AUTOSAR XML (schema 4-3-0)
package /Schaeffler/Components/ASW_EDS_TQ250
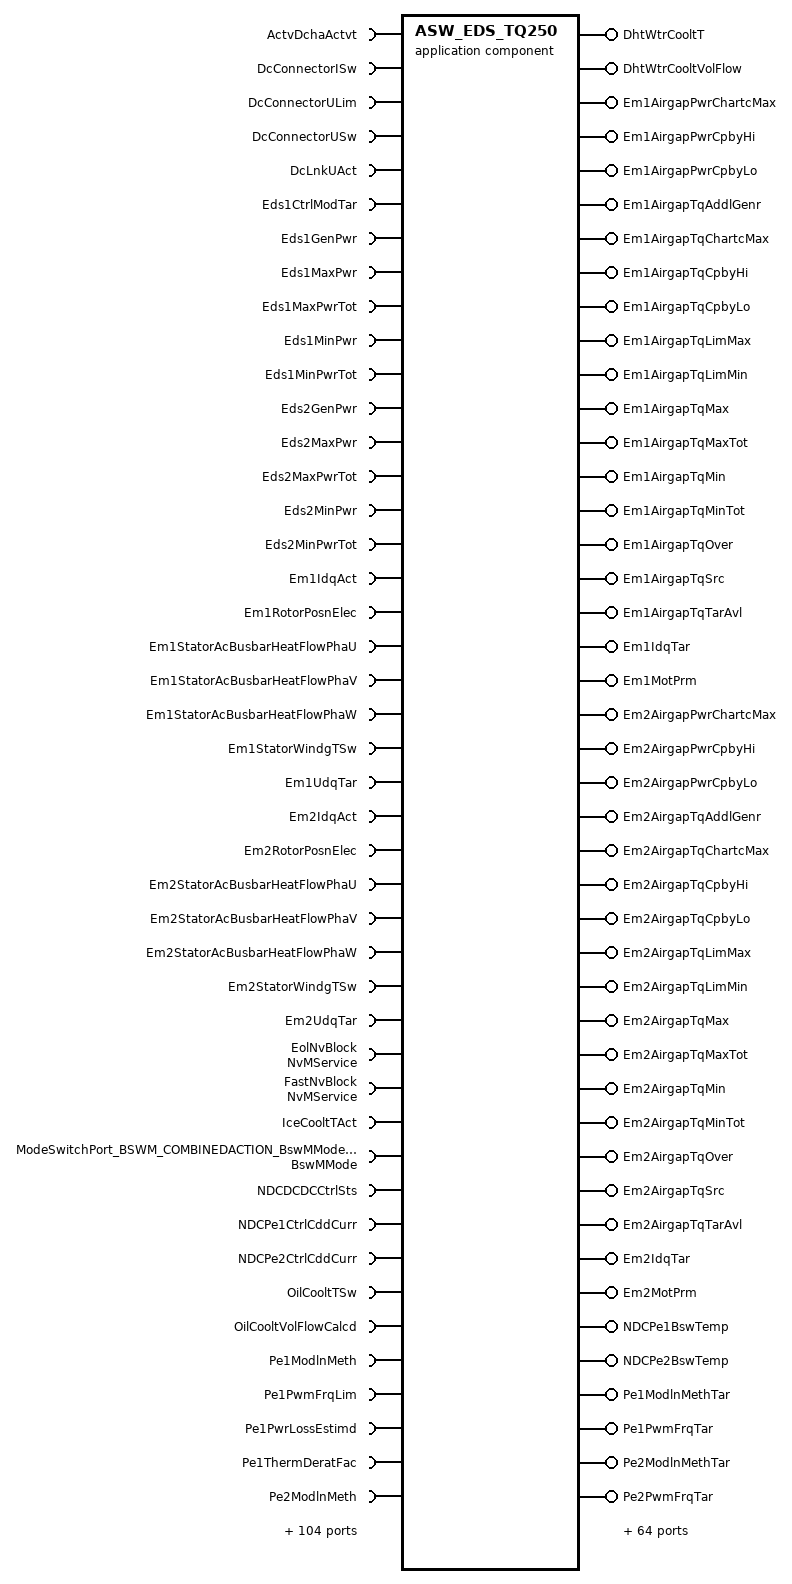
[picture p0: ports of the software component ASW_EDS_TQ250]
  application sw component type ASW_EDS_TQ250
    5 x require port:
      ActvDchaActvt: nonqueued-receiver-com-spec{data-element=FlgVal, filter=data-filter-type=ALWAYS, init-value=0}, required-interface=ActvDchaActvt
      DcConnectorISw: nonqueued-receiver-com-spec{data-element=ValSts, filter=data-filter-type=ALWAYS, init-value=fields=[0 Ampere, 0 Ampere]}, required-interface=DcConnectorISw
      DcConnectorULim: required-interface=DcConnectorULim
        required-com-specs:
          data-element=UMinValSts, filter=data-filter-type=ALWAYS, init-value=fields=[0 V, 0 V]
          data-element=UMaxValSts, filter=data-filter-type=ALWAYS, init-value=fields=[0 V, 0 V]
      DcConnectorUSw: required-interface=DcConnectorUSw
        required-com-specs:
          data-element=UVal, filter=data-filter-type=ALWAYS, init-value=0 Volt
          data-element=UQf, init-value=0
          data-element=ValSts, filter=data-filter-type=ALWAYS, init-value=fields=[0, 0]
      DcLnkUAct: nonqueued-receiver-com-spec{data-element=ValSts, filter=data-filter-type=ALWAYS, init-value=fields=[0, 0]}, required-interface=DcLnkUAct
    provide port DhtWtrCooltT: nonqueued-sender-com-spec{data-element=TTarValSts, init-value=fields=[0 degC, 0 degC]}, provided-interface=DhtWtrCooltT
    provide port DhtWtrCooltVolFlow: nonqueued-sender-com-spec{data-element=VolTarValSts, init-value=fields=[0 lpmin, 0 lpmin]}, provided-interface=DhtWtrCooltVolFlow
    11 x require port:
      Eds1CtrlModTar: nonqueued-receiver-com-spec{data-element=ModVal, filter=data-filter-type=ALWAYS, init-value=0}, required-interface=Eds1CtrlModTar
      Eds1GenPwr: nonqueued-receiver-com-spec{data-element=PwrValSts, filter=data-filter-type=ALWAYS, init-value=fields=[0 W, 0 W]}, required-interface=Eds1GenPwr
      Eds1MaxPwr: nonqueued-receiver-com-spec{data-element=PwrValSts, filter=data-filter-type=ALWAYS, init-value=fields=[0 W, 0 W]}, required-interface=Eds1MaxPwr
      Eds1MaxPwrTot: nonqueued-receiver-com-spec{data-element=PwrValSts, filter=data-filter-type=ALWAYS, init-value=fields=[0 W, 0 W]}, required-interface=Eds1MaxPwrTot
      Eds1MinPwr: nonqueued-receiver-com-spec{data-element=PwrValSts, filter=data-filter-type=ALWAYS, init-value=fields=[0 W, 0 W]}, required-interface=Eds1MinPwr
      Eds1MinPwrTot: nonqueued-receiver-com-spec{data-element=PwrValSts, filter=data-filter-type=ALWAYS, init-value=fields=[0 W, 0 W]}, required-interface=Eds1MinPwrTot
      Eds2GenPwr: nonqueued-receiver-com-spec{data-element=PwrValSts, filter=data-filter-type=ALWAYS, init-value=fields=[0 W, 0 W]}, required-interface=Eds2GenPwr
      Eds2MaxPwr: nonqueued-receiver-com-spec{data-element=PwrValSts, filter=data-filter-type=ALWAYS, init-value=fields=[0 W, 0 W]}, required-interface=Eds2MaxPwr
      Eds2MaxPwrTot: nonqueued-receiver-com-spec{data-element=PwrValSts, filter=data-filter-type=ALWAYS, init-value=fields=[0 W, 0 W]}, required-interface=Eds2MaxPwrTot
      Eds2MinPwr: nonqueued-receiver-com-spec{data-element=PwrValSts, filter=data-filter-type=ALWAYS, init-value=fields=[0 W, 0 W]}, required-interface=Eds2MinPwr
      Eds2MinPwrTot: nonqueued-receiver-com-spec{data-element=PwrValSts, filter=data-filter-type=ALWAYS, init-value=fields=[0 W, 0 W]}, required-interface=Eds2MinPwrTot
    16 x provide port:
      Em1AirgapPwrChartcMax: nonqueued-sender-com-spec{data-element=PwrMaxValSts, init-value=fields=[0 Watt, 0 Watt]}, provided-interface=Em1AirgapPwrChartcMax
      Em1AirgapPwrCpbyHi: nonqueued-sender-com-spec{data-element=PwrValSts, init-value=fields=[0 Watt, 0 Watt]}, provided-interface=Em1AirgapPwrCpbyHi
      Em1AirgapPwrCpbyLo: nonqueued-sender-com-spec{data-element=PwrValSts, init-value=fields=[0 Watt, 0 Watt]}, provided-interface=Em1AirgapPwrCpbyLo
      Em1AirgapTqAddlGenr: provided-interface=Em1AirgapTqAddlGenr
        provided-com-specs:
          data-element=TqQf, init-value=0
          data-element=TqVal, init-value=0 Nm
          data-element=TqValSts, init-value=fields=[0 Nm, 0]
      Em1AirgapTqChartcMax: nonqueued-sender-com-spec{data-element=TqMaxValSts, init-value=fields=[0 Watt, 0 Watt]}, provided-interface=Em1AirgapTqChartcMax
      Em1AirgapTqCpbyHi: nonqueued-sender-com-spec{data-element=TqValSts, init-value=fields=[0 Nm, 0 Nm]}, provided-interface=Em1AirgapTqCpbyHi
      Em1AirgapTqCpbyLo: nonqueued-sender-com-spec{data-element=TqValSts, init-value=fields=[0 Nm, 0 Nm]}, provided-interface=Em1AirgapTqCpbyLo
      Em1AirgapTqLimMax: provided-com-specs=[{data-element=TqMaxVal, init-value=0}, {data-element=TqMaxValSts, init-value=fields=[New:0, Status:0]}], provided-interface=Em1AirgapTqLimMax
      Em1AirgapTqLimMin: nonqueued-sender-com-spec{data-element=TqMinValSts, init-value=fields=[0 Nm, 0 Nm]}, provided-interface=Em1AirgapTqLimMin
      Em1AirgapTqMax: nonqueued-sender-com-spec{data-element=TqMaxValSts, init-value=fields=[0 Nm, 0 Nm]}, provided-interface=Em1AirgapTqMax
      Em1AirgapTqMaxTot: nonqueued-sender-com-spec{data-element=TqMaxValSts, init-value=fields=[0 Nm, 0 Nm]}, provided-interface=Em1AirgapTqMaxTot
      Em1AirgapTqMin: nonqueued-sender-com-spec{data-element=TqMinValSts, init-value=fields=[0 Nm, 0 Nm]}, provided-interface=Em1AirgapTqMin
      Em1AirgapTqMinTot: nonqueued-sender-com-spec{data-element=TqMinValSts, init-value=fields=[0 Nm, 0 Nm]}, provided-interface=Em1AirgapTqMinTot
      Em1AirgapTqOver: nonqueued-sender-com-spec{data-element=FlgVal, init-value=0}, provided-interface=Em1AirgapTqOver
      Em1AirgapTqSrc: nonqueued-sender-com-spec{data-element=SrcVal, init-value=0}, provided-interface=Em1AirgapTqSrc
      Em1AirgapTqTarAvl: nonqueued-sender-com-spec{data-element=TqVal, init-value=0 NwtMtr}, provided-interface=Em1AirgapTqTarAvl
    require port Em1IdqAct: required-interface=Em1IdqAct
      required-com-specs:
        data-element=IdQf, filter=data-filter-type=ALWAYS, init-value=0
        data-element=IdVal, filter=data-filter-type=ALWAYS, init-value=0 Ampere
        data-element=IqQf, filter=data-filter-type=ALWAYS, init-value=0
        data-element=IqVal, filter=data-filter-type=ALWAYS, init-value=0 Ampere
    provide port Em1IdqTar: provided-interface=Em1IdqTar
      provided-com-specs:
        data-element=IdQf, init-value=0
        data-element=IdVal, init-value=0 Ampere
        data-element=IqQf, init-value=0
        data-element=IqVal, init-value=0 Ampere
    provide port Em1MotPrm: provided-interface=Em1MotPrm
      provided-com-specs:
        data-element=FlxdQf, init-value=0
        data-element=FlxdVal, init-value=0 Weber
        data-element=FlxPrmntMagQf, init-value=0
        data-element=FlxPrmntMagVal, init-value=0.0237 Weber
        data-element=FlxqQf, init-value=0
        data-element=FlxqVal, init-value=0 Weber
        data-element=LdQf, init-value=0
        data-element=LdVal, init-value=0.00012 Henry
        data-element=LqQf, init-value=0
        data-element=LqVal, init-value=0.000277 Henry
        data-element=RVal, init-value=0.0086 Ohm
        data-element=LqDiffVal, init-value=0.000277 Henry
        data-element=LdDiffVal, init-value=0.00012 Henry
    6 x require port:
      Em1RotorPosnElec: required-interface=Em1RotorPosnElec
        required-com-specs:
          data-element=PosnQf, filter=data-filter-type=ALWAYS, init-value=0
          data-element=PosnVal, filter=data-filter-type=ALWAYS, init-value=0 rad
      Em1StatorAcBusbarHeatFlowPhaU: required-interface=Em1StatorAcBusbarHeatFlowPhaU
        required-com-specs:
          data-element=HeatFlowPhaUVal, filter=data-filter-type=ALWAYS, init-value=65 Watt
          data-element=HeatFlowPhaUValQf, filter=data-filter-type=ALWAYS, init-value=0
      Em1StatorAcBusbarHeatFlowPhaV: required-interface=Em1StatorAcBusbarHeatFlowPhaV
        required-com-specs:
          data-element=HeatFlowPhaVVal, filter=data-filter-type=ALWAYS, init-value=65 Watt
          data-element=HeatFlowPhaVValQf, filter=data-filter-type=ALWAYS, init-value=0
      Em1StatorAcBusbarHeatFlowPhaW: required-interface=Em1StatorAcBusbarHeatFlowPhaW
        required-com-specs:
          data-element=HeatFlowPhaWVal, filter=data-filter-type=ALWAYS, init-value=65 Watt
          data-element=HeatFlowPhaWValQf, filter=data-filter-type=ALWAYS, init-value=0
      Em1StatorWindgTSw: nonqueued-receiver-com-spec{data-element=TValSts, init-value=fields=[0 degC, 0 degC]}, required-interface=Em1StatorWindgTSw
      Em1UdqTar: required-interface=Em1UdqTar
        required-com-specs:
          data-element=UdVal, filter=data-filter-type=ALWAYS, init-value=0 Volt
          data-element=UqVal, filter=data-filter-type=ALWAYS, init-value=0 Volt
    16 x provide port:
      Em2AirgapPwrChartcMax: nonqueued-sender-com-spec{data-element=PwrMaxValSts, init-value=fields=[0 Watt, 0 Watt]}, provided-interface=Em2AirgapPwrChartcMax
      Em2AirgapPwrCpbyHi: nonqueued-sender-com-spec{data-element=PwrValSts, init-value=fields=[0 Watt, 0 Watt]}, provided-interface=Em2AirgapPwrCpbyHi
      Em2AirgapPwrCpbyLo: nonqueued-sender-com-spec{data-element=PwrValSts, init-value=fields=[0 Watt, 0 Watt]}, provided-interface=Em2AirgapPwrCpbyLo
      Em2AirgapTqAddlGenr: nonqueued-sender-com-spec{data-element=TqValSts, init-value=fields=[0 Nm, 0]}, provided-interface=Em2AirgapTqAddlGenr
      Em2AirgapTqChartcMax: nonqueued-sender-com-spec{data-element=TqMaxValSts, init-value=fields=[0 Nm, 0 Nm]}, provided-interface=Em2AirgapTqChartcMax
      Em2AirgapTqCpbyHi: nonqueued-sender-com-spec{data-element=TqValSts, init-value=fields=[0 Nm, 0 Nm]}, provided-interface=Em2AirgapTqCpbyHi
      Em2AirgapTqCpbyLo: nonqueued-sender-com-spec{data-element=TqValSts, init-value=fields=[0 Nm, 0 Nm]}, provided-interface=Em2AirgapTqCpbyLo
      Em2AirgapTqLimMax: nonqueued-sender-com-spec{data-element=TqMaxValSts, init-value=fields=[0 Nm, 0 Nm]}, provided-interface=Em2AirgapTqLimMax
      Em2AirgapTqLimMin: nonqueued-sender-com-spec{data-element=TqMinValSts, init-value=fields=[0 Nm, 0 Nm]}, provided-interface=Em2AirgapTqLimMin
      Em2AirgapTqMax: nonqueued-sender-com-spec{data-element=TqMaxValSts, init-value=fields=[1023 Nm, 0 Nm]}, provided-interface=Em2AirgapTqMax
      Em2AirgapTqMaxTot: nonqueued-sender-com-spec{data-element=TqMaxValSts, init-value=fields=[0 Nm, 0 Nm]}, provided-interface=Em2AirgapTqMaxTot
      Em2AirgapTqMin: nonqueued-sender-com-spec{data-element=TqMinValSts, init-value=fields=[1023 Nm, 0 Nm]}, provided-interface=Em2AirgapTqMin
      Em2AirgapTqMinTot: nonqueued-sender-com-spec{data-element=TqMinValSts, init-value=fields=[0 Nm, 0 Nm]}, provided-interface=Em2AirgapTqMinTot
      Em2AirgapTqOver: nonqueued-sender-com-spec{data-element=FlgVal, init-value=0}, provided-interface=Em2AirgapTqOver
      Em2AirgapTqSrc: nonqueued-sender-com-spec{data-element=SrcVal, init-value=0}, provided-interface=Em2AirgapTqSrc
      Em2AirgapTqTarAvl: nonqueued-sender-com-spec{data-element=TqVal, init-value=0 NwtMtr}, provided-interface=Em2AirgapTqTarAvl
    require port Em2IdqAct: required-interface=Em2IdqAct
      required-com-specs:
        data-element=IdQf, filter=data-filter-type=ALWAYS, init-value=0
        data-element=IdVal, filter=data-filter-type=ALWAYS, init-value=0 Ampere
        data-element=IqQf, filter=data-filter-type=ALWAYS, init-value=0
        data-element=IqVal, filter=data-filter-type=ALWAYS, init-value=0 Ampere
    provide port Em2IdqTar: provided-interface=Em2IdqTar
      provided-com-specs:
        data-element=IdQf, init-value=0
        data-element=IdVal, init-value=0 Ampere
        data-element=IqQf, init-value=0
        data-element=IqVal, init-value=0 Ampere
    provide port Em2MotPrm: provided-interface=Em2MotPrm
      provided-com-specs:
        data-element=FlxdQf, init-value=0
        data-element=FlxdVal, init-value=0 Weber
        data-element=FlxPrmntMagQf, init-value=0
        data-element=FlxPrmntMagVal, init-value=0.064 Weber
        data-element=FlxqQf, init-value=0
        data-element=FlxqVal, init-value=0 Weber
        data-element=LdQf, init-value=0
        data-element=LdVal, init-value=0.000166 Henry
        data-element=LqQf, init-value=0
        data-element=LqVal, init-value=0.000503 Henry
        data-element=RVal, init-value=0.011 Ohm
        data-element=LqDiffVal, init-value=0.000503 Henry
        data-element=LdDiffVal, init-value=0.000166 Henry
    11 x require port:
      Em2RotorPosnElec: required-interface=Em2RotorPosnElec
        required-com-specs:
          data-element=PosnQf, filter=data-filter-type=ALWAYS, init-value=0
          data-element=PosnVal, filter=data-filter-type=ALWAYS, init-value=0 rad
      Em2StatorAcBusbarHeatFlowPhaU: required-interface=Em2StatorAcBusbarHeatFlowPhaU
        required-com-specs:
          data-element=HeatFlowPhaUVal, filter=data-filter-type=ALWAYS, init-value=65 Watt
          data-element=HeatFlowPhaUValQf, filter=data-filter-type=ALWAYS, init-value=0
      Em2StatorAcBusbarHeatFlowPhaV: required-interface=Em2StatorAcBusbarHeatFlowPhaV
        required-com-specs:
          data-element=HeatFlowPhaVVal, filter=data-filter-type=ALWAYS, init-value=65 Watt
          data-element=HeatFlowPhaVValQf, filter=data-filter-type=ALWAYS, init-value=0
      Em2StatorAcBusbarHeatFlowPhaW: required-interface=Em2StatorAcBusbarHeatFlowPhaW
        required-com-specs:
          data-element=HeatFlowPhaWVal, filter=data-filter-type=ALWAYS, init-value=65 Watt
          data-element=HeatFlowPhaWValQf, filter=data-filter-type=ALWAYS, init-value=0
      Em2StatorWindgTSw: nonqueued-receiver-com-spec{data-element=TValSts, filter=data-filter-type=ALWAYS, init-value=fields=[0 degC, 0 degC]}, required-interface=Em2StatorWindgTSw
      Em2UdqTar: required-interface=Em2UdqTar
        required-com-specs:
          data-element=UdVal, filter=data-filter-type=ALWAYS, init-value=0 Volt
          data-element=UqVal, filter=data-filter-type=ALWAYS, init-value=0 Volt
      EolNvBlock: client-com-spec=SetRamBlockStatus, required-interface=NvMService
      FastNvBlock: client-com-spec=SetRamBlockStatus, required-interface=NvMService
      IceCooltTAct: required-interface=IceCooltTAct
        required-com-specs:
          data-element=TVal, filter=data-filter-type=ALWAYS, init-value=0 degC
          data-element=ValSts, init-value=fields=[0 degC, 0]
      ModeSwitchPort_BSWM_COMBINEDACTION_BswMMode_PortInterfaces_BswMMode: mode-switch-receiver-com-spec=CurrentMode, required-interface=BswMMode
      NDCDCDCCtrlSts: nonqueued-receiver-com-spec{data-element=DCDCStatus, filter=data-filter-type=ALWAYS, init-value=0}, required-interface=NDCDCDCCtrlSts
    provide port NDCPe1BswTemp: provided-interface=NDCPe1BswTemp
      provided-com-specs:
        data-element=AcBusbarTEstimdPhaUVal, init-value=20 DegCgrd
        data-element=AcBusbarTEstimdPhaVVal, init-value=20 DegCgrd
        data-element=AcBusbarTEstimdPhaWVal, init-value=20 DegCgrd
    require port NDCPe1CtrlCddCurr: required-interface=NDCPe1CtrlCddCurr
      required-com-specs:
        data-element=IdcVal, filter=data-filter-type=ALWAYS, init-value=0 Ampere
        data-element=IdcValSts, filter=data-filter-type=ALWAYS, init-value=fields=[0 A, 0 A]
    provide port NDCPe2BswTemp: provided-interface=NDCPe2BswTemp
      provided-com-specs:
        data-element=AcBusbarTEstimdPhaUVal, init-value=20 DegCgrd
        data-element=AcBusbarTEstimdPhaVVal, init-value=20 DegCgrd
        data-element=AcBusbarTEstimdPhaWVal, init-value=20 DegCgrd
    4 x require port:
      NDCPe2CtrlCddCurr: required-interface=NDCPe2CtrlCddCurr
        required-com-specs:
          data-element=IdcVal, filter=data-filter-type=ALWAYS, init-value=0 Ampere
          data-element=IdcValSts, filter=data-filter-type=ALWAYS, init-value=fields=[0 A, 0 A]
      OilCooltTSw: nonqueued-receiver-com-spec{data-element=TValSts, filter=data-filter-type=ALWAYS, init-value=fields=[0 degC, 0 degC]}, required-interface=OilCooltTSw
      OilCooltVolFlowCalcd: nonqueued-receiver-com-spec{data-element=VolFlowValSts, filter=data-filter-type=ALWAYS, init-value=fields=[0 lpmin, 0 lpmin]}, required-interface=OilCooltVolFlowCalcd
      Pe1ModlnMeth: nonqueued-receiver-com-spec{data-element=ModlnMeth, filter=data-filter-type=ALWAYS, init-value=1}, required-interface=Pe1ModlnMeth
    provide port Pe1ModlnMethTar: nonqueued-sender-com-spec{data-element=Val, init-value=1}, provided-interface=Pe1ModlnMethTar
    require port Pe1PwmFrqLim: required-interface=Pe1PwmFrqLim
      required-com-specs:
        data-element=FrqMaxVal, filter=data-filter-type=ALWAYS, init-value=10000 Hz
        data-element=FrqMinVal, filter=data-filter-type=ALWAYS, init-value=10000 Hz
    provide port Pe1PwmFrqTar: nonqueued-sender-com-spec{data-element=FrqVal, init-value=10000 Hz}, provided-interface=Pe1PwmFrqTar
    require port Pe1PwrLossEstimd: required-interface=Pe1PwrLossEstimd
      required-com-specs:
        data-element=PwrVal, filter=data-filter-type=ALWAYS, init-value=0 Watt
        data-element=PwrValQf, filter=data-filter-type=ALWAYS, init-value=0
    require port Pe1ThermDeratFac: required-interface=Pe1ThermDeratFac
      required-com-specs:
        data-element=MaxVal, filter=data-filter-type=ALWAYS, init-value=1 Perc
        data-element=MaxValSts, filter=data-filter-type=ALWAYS, init-value=fields=[0, 0]
    require port Pe2ModlnMeth: nonqueued-receiver-com-spec{data-element=ModlnMeth, filter=data-filter-type=ALWAYS, init-value=1}, required-interface=Pe2ModlnMeth
    provide port Pe2ModlnMethTar: nonqueued-sender-com-spec{data-element=Val, init-value=1 State}, provided-interface=Pe2ModlnMethTar
    require port Pe2PwmFrqLim: required-interface=Pe2PwmFrqLim
      required-com-specs:
        data-element=FrqMaxVal, filter=data-filter-type=ALWAYS, init-value=10000 Hz
        data-element=FrqMinVal, filter=data-filter-type=ALWAYS, init-value=10000 Hz
    provide port Pe2PwmFrqTar: nonqueued-sender-com-spec{data-element=FrqVal, init-value=10000 Hz}, provided-interface=Pe2PwmFrqTar
    8 x require port:
      Pe2PwrLossEstimd: required-interface=Pe2PwrLossEstimd
        required-com-specs:
          data-element=PwrVal, filter=data-filter-type=ALWAYS, init-value=0 Watt
          data-element=PwrValQf, filter=data-filter-type=ALWAYS, init-value=0
      Pe2ThermDeratFac: required-interface=Pe2ThermDeratFac
        required-com-specs:
          data-element=MaxVal, filter=data-filter-type=ALWAYS, init-value=1 Perc
          data-element=MaxValSts, init-value=fields=[0, 0]
      PeDcDcCnvrTDeratFac: required-interface=PeDcDcCnvrTDeratFac
        required-com-specs:
          data-element=FacVal, filter=data-filter-type=ALWAYS, init-value=1
          data-element=FacValSts, init-value=fields=[0, 0]
      PeWtrCooltOutlTEstimd: required-interface=PeWtrCooltOutlTEstimd
        required-com-specs:
          data-element=TVal, filter=data-filter-type=ALWAYS, init-value=20 degC
          data-element=TValQf, filter=data-filter-type=ALWAYS, init-value=0
      PeWtrCooltTTar: nonqueued-receiver-com-spec{data-element=TVal, filter=data-filter-type=ALWAYS, init-value=20 DegCgrd}, required-interface=PeWtrCooltTTar
      PeWtrCooltVolFlowTar: nonqueued-receiver-com-spec{data-element=VolFlowVal, filter=data-filter-type=ALWAYS, init-value=8 lppermin}, required-interface=PeWtrCooltVolFlowTar
      RlySts: nonqueued-receiver-com-spec{data-element=StsVal, filter=data-filter-type=ALWAYS, init-value=0}, required-interface=RlySts
      SafeNvBlock: client-com-spec=SetRamBlockStatus, required-interface=NvMService
    provide port SmpOilTEstimd: nonqueued-sender-com-spec{data-element=TValSts, init-value=fields=[0 degC, 0 degC]}, provided-interface=SmpOilTEstimd
    provide port TOilCooltVolFlow: nonqueued-sender-com-spec{data-element=VolTarValSts, init-value=fields=[0 lpmin, 0 lpmin]}, provided-interface=TOilCooltVolFlow
    require port ToothNr: nonqueued-receiver-com-spec{data-element=NrVal, filter=data-filter-type=ALWAYS, init-value=0}, required-interface=ToothNr
    require port UR_ComMUser_0: client-com-spec=RequestComMode, required-interface=ComM_UserRequest
    require port VehTiOff: nonqueued-receiver-com-spec{data-element=TiValSts, filter=data-filter-type=ALWAYS, init-value=fields=[0 min, 0 min]}, required-interface=VehTiOff
    provide port Em2TqCtrlModActvt: nonqueued-sender-com-spec{data-element=PECInIf_b_tqCtl_VW, init-value=0}, provided-interface=PECInIf_b_tqCtl_VW
    require port Em2AirgapTqDampgSts: nonqueued-receiver-com-spec{data-element=PECOutIf_bDampCtl_VW, init-value=0}, required-interface=PECOutIf_bDampCtl_VW
    require port Em2AirgapTqTarTot: nonqueued-receiver-com-spec{data-element=PECOutIf_tqSp_VW, init-value=0 NwtMtr}, required-interface=PECOutIf_tqSp_VW
    require port Em2AirgapTqLimLo: nonqueued-receiver-com-spec{data-element=PECOutIf_tqSpSpdlMin_VW, init-value=0 NwtMtr}, required-interface=PECOutIf_tqSpSpdlMin_VW
    provide port AswReadyForShutdown: nonqueued-sender-com-spec{data-element=FlgVal, init-value=0}, provided-interface=AswReadyForShutdown
    11 x require port:
      DcConnectorILim: required-interface=DcConnectorILim
        required-com-specs:
          data-element=MinIValSts, filter=data-filter-type=ALWAYS, init-value=fields=[0 V, 0 A]
          data-element=MaxIValSts, filter=data-filter-type=ALWAYS, init-value=fields=[0 A, 0 A]
      Pe1PhaIAcRmsSwPhaU: nonqueued-receiver-com-spec{data-element=IVal, filter=data-filter-type=ALWAYS, init-value=0 Ampere}, required-interface=Pe1PhaIAcRmsSwPhaU
      Pe1PhaIAcRmsSwPhaV: nonqueued-receiver-com-spec{data-element=IVal, filter=data-filter-type=ALWAYS, init-value=0 Ampere}, required-interface=Pe1PhaIAcRmsSwPhaV
      Pe1PhaIAcRmsSwPhaW: nonqueued-receiver-com-spec{data-element=IVal, filter=data-filter-type=ALWAYS, init-value=0 Ampere}, required-interface=Pe1PhaIAcRmsSwPhaW
      Pe2PhaIAcRmsSwPhaU: nonqueued-receiver-com-spec{data-element=IVal, filter=data-filter-type=ALWAYS, init-value=0 Ampere}, required-interface=Pe2PhaIAcRmsSwPhaU
      Pe2PhaIAcRmsSwPhaV: nonqueued-receiver-com-spec{data-element=IVal, filter=data-filter-type=ALWAYS, init-value=0 Ampere}, required-interface=Pe2PhaIAcRmsSwPhaV
      Pe2PhaIAcRmsSwPhaW: nonqueued-receiver-com-spec{data-element=IVal, filter=data-filter-type=ALWAYS, init-value=0 Ampere}, required-interface=Pe2PhaIAcRmsSwPhaW
      AmbTAct: required-interface=AmbTAct
        required-com-specs:
          data-element=TVal, init-value=20 DegCgrd
          data-element=ValSts, filter=data-filter-type=ALWAYS, init-value=fields=[0 degC, 0]
      Em1AirgapTqTar: nonqueued-receiver-com-spec{data-element=TqValSts, filter=data-filter-type=ALWAYS, init-value=fields=[0 Nm, 0 Nm]}, required-interface=Em1AirgapTqTar
      Em2AirgapTqTar: required-interface=Em2AirgapTqTar
        required-com-specs:
          data-element=TqVal, filter=data-filter-type=ALWAYS, init-value=0 NwtMtr
          data-element=TqValSts, filter=data-filter-type=ALWAYS, init-value=fields=[0 Nm, 0 Nm]
      WtrCooltInlVolFlowAct: required-interface=WtrCooltInlVolFlowAct
        required-com-specs:
          data-element=VolVal, filter=data-filter-type=ALWAYS, init-value=0 lppermin
          data-element=ValSts, filter=data-filter-type=ALWAYS, init-value=fields=[0 lpmin, 0 lpmin]
    5 x provide port:
      EM1DetnFreeVolt: nonqueued-sender-com-spec{data-element=StsVal, init-value=0 State}, provided-interface=EM1DetnFreeVolt
      EM1DetnOpenHVWire: nonqueued-sender-com-spec{data-element=StsVal, init-value=0 State}, provided-interface=EM1DetnOpenHVWire
      EM2DetnFreeVolt: nonqueued-sender-com-spec{data-element=StsVal, init-value=0 State}, provided-interface=EM2DetnFreeVolt
      EM2DetnOpenHVWire: nonqueued-sender-com-spec{data-element=StsVal, init-value=0 State}, provided-interface=EM2DetnOpenHVWire
      DcLnkUTar: provided-com-specs=[{data-element=UVal, init-value=0 Volt}, {data-element=ValSts, init-value=fields=[0 V, 0 V]}], provided-interface=DcLnkUTar
    12 x require port:
      Eds2CtrlModTar: nonqueued-receiver-com-spec{data-element=ModVal, filter=data-filter-type=ALWAYS, init-value=0}, required-interface=Eds2CtrlModTar
      Em1CurrMaxLim: required-interface=Em1CurrMaxLim
        required-com-specs:
          data-element=IMaxVal, filter=data-filter-type=ALWAYS, init-value=0
          data-element=IMaxValSts, filter=data-filter-type=ALWAYS, init-value=fields=[0 A, 0 A]
      Em1CurrMinLim: required-interface=Em1CurrMinLim
        required-com-specs:
          data-element=IMinVal, filter=data-filter-type=ALWAYS, init-value=0
          data-element=IMinValSts, filter=data-filter-type=ALWAYS, init-value=fields=[0 A, 0 A]
      Em1VoltMaxLim: required-interface=Em1VoltMaxLim
        required-com-specs:
          data-element=UMaxVal, filter=data-filter-type=ALWAYS, init-value=0
          data-element=UMaxValSts, filter=data-filter-type=ALWAYS, init-value=fields=[0 V, 0 V]
      Em1VoltMinLim: required-interface=Em1VoltMinLim
        required-com-specs:
          data-element=UMinVal, filter=data-filter-type=ALWAYS, init-value=0
          data-element=UMinValSts, filter=data-filter-type=ALWAYS, init-value=fields=[0 V, 0 V]
      Em2CurrMaxLim: required-interface=Em2CurrMaxLim
        required-com-specs:
          data-element=IMaxVal, filter=data-filter-type=ALWAYS, init-value=0
          data-element=IMaxValSts, filter=data-filter-type=ALWAYS, init-value=fields=[0 A, 0 A]
      Em2CurrMinLim: required-interface=Em2CurrMinLim
        required-com-specs:
          data-element=IMinVal, filter=data-filter-type=ALWAYS, init-value=0
          data-element=IMinValSts, filter=data-filter-type=ALWAYS, init-value=fields=[0 A, 0 A]
      Em2VoltMaxLim: required-interface=Em2VoltMaxLim
        required-com-specs:
          data-element=UMaxVal, filter=data-filter-type=ALWAYS, init-value=0
          data-element=UMaxValSts, filter=data-filter-type=ALWAYS, init-value=fields=[0 V, 0 V]
      Em2VoltMinLim: required-interface=Em2VoltMinLim
        required-com-specs:
          data-element=UMinVal, filter=data-filter-type=ALWAYS, init-value=0
          data-element=UMinValSts, filter=data-filter-type=ALWAYS, init-value=fields=[0 V, 0 V]
      Em2TqLimTracCtrl: required-interface=Em2TqLimTracCtrl
        required-com-specs:
          data-element=TqMinVal, filter=data-filter-type=ALWAYS, init-value=0 Nm
          data-element=TqMaxVal, filter=data-filter-type=ALWAYS, init-value=0 Nm
      Em2SpdAct: required-interface=Em2SpdAct
        required-com-specs:
          data-element=SpdQf, filter=data-filter-type=ALWAYS, init-value=0
          data-element=SpdVal, filter=data-filter-type=ALWAYS, init-value=0 Rpm
      Em1SpdAct: required-interface=Em1SpdAct
        required-com-specs:
          data-element=SpdQf, filter=data-filter-type=ALWAYS, init-value=0
          data-element=SpdVal, filter=data-filter-type=ALWAYS, init-value=0 Rpm
    6 x provide port:
      Em1SpdActvScLoInit: nonqueued-sender-com-spec{data-element=SpdValSts, init-value=fields=[0 Rpm, 0 Rpm]}, provided-interface=Em1SpdActvScLoInit
      Em2SpdActvScLoInit: nonqueued-sender-com-spec{data-element=SpdValSts, init-value=fields=[0 Rpm, 0 Rpm]}, provided-interface=Em2SpdActvScLoInit
      DcDcModeTar: nonqueued-sender-com-spec{data-element=StsVal, init-value=0}, provided-interface=DcDcModeTar
      Em1ActvDchaSrcQm: nonqueued-sender-com-spec{data-element=FlgVal, init-value=0}, provided-interface=Em1ActvDchaSrcQm
      Em1PwmDcSrcQm: nonqueued-sender-com-spec{data-element=SrcVal, init-value=1}, provided-interface=Em1PwmDcSrcQm
      Em2PwmDcSrcQm: nonqueued-sender-com-spec{data-element=SrcVal, init-value=1}, provided-interface=Em2PwmDcSrcQm
    14 x require port:
      R_MonAProtSpdOutLimHiEm1: required-interface=DiagnosticInfo
        required-com-specs:
          GetEventExtendedDataRecord
          GetEventFreezeFrameData
          GetFaultDetectionCounter
          GetDTCOfEvent
          GetEventTested
          GetEventFailed
          GetEventStatus
          GetEventUdsStatus
          GetMonitorStatus
          GetEventAvailable
          GetEventFreezeFrameDataEx
          GetEventExtendedDataRecordEx
          GetDebouncingOfEvent
      R_MonAProtSpdOutLimHiEm2: required-interface=DiagnosticInfo
        required-com-specs:
          GetEventExtendedDataRecord
          GetEventFreezeFrameData
          GetFaultDetectionCounter
          GetDTCOfEvent
          GetEventTested
          GetEventFailed
          GetEventStatus
          GetEventUdsStatus
          GetMonitorStatus
          GetEventAvailable
          GetEventFreezeFrameDataEx
          GetEventExtendedDataRecordEx
          GetDebouncingOfEvent
      R_MonAProtTempOutLimHiEm1: required-interface=DiagnosticInfo
        required-com-specs:
          GetEventExtendedDataRecord
          GetEventFreezeFrameData
          GetFaultDetectionCounter
          GetDTCOfEvent
          GetEventTested
          GetEventFailed
          GetEventStatus
          GetEventUdsStatus
          GetMonitorStatus
          GetEventAvailable
          GetEventFreezeFrameDataEx
          GetEventExtendedDataRecordEx
          GetDebouncingOfEvent
      P_MonAProtTempOutLimHiEm1: required-interface=DiagnosticMonitor
        required-com-specs:
          ClearPrestoredFreezeFrame
          PrestoreFreezeFrame
          ResetEventDebounceStatus
          ResetEventStatus
          SetEventStatus
          SetEventDisabled
      P_MonAProtSpdOutLimHiEm1: required-interface=DiagnosticMonitor
        required-com-specs:
          ClearPrestoredFreezeFrame
          PrestoreFreezeFrame
          ResetEventDebounceStatus
          ResetEventStatus
          SetEventStatus
          SetEventDisabled
      P_MonAProtSpdOutLimHiEm2: required-interface=DiagnosticMonitor
        required-com-specs:
          ClearPrestoredFreezeFrame
          PrestoreFreezeFrame
          ResetEventDebounceStatus
          ResetEventStatus
          SetEventStatus
          SetEventDisabled
      R_MonAProtTempOutLimHiEm2: required-interface=DiagnosticInfo
        required-com-specs:
          GetEventExtendedDataRecord
          GetEventFreezeFrameData
          GetFaultDetectionCounter
          GetDTCOfEvent
          GetEventTested
          GetEventFailed
          GetEventStatus
          GetEventUdsStatus
          GetMonitorStatus
          GetEventAvailable
          GetEventFreezeFrameDataEx
          GetEventExtendedDataRecordEx
          GetDebouncingOfEvent
      P_MonAProtTempOutLimHiEm2: required-interface=DiagnosticMonitor
        required-com-specs:
          ClearPrestoredFreezeFrame
          PrestoreFreezeFrame
          ResetEventDebounceStatus
          ResetEventStatus
          SetEventStatus
          SetEventDisabled
      Em2AirgapTqAllwdMin: nonqueued-receiver-com-spec{data-element=TqMinValSts, filter=data-filter-type=ALWAYS, init-value=fields=[0 Nm, 0 Nm]}, required-interface=Em2AirgapTqAllwdMin
      Em2AirgapTqAllwdMax: nonqueued-receiver-com-spec{data-element=TqMaxValSts, filter=data-filter-type=ALWAYS, init-value=fields=[0 Nm, 0 Nm]}, required-interface=Em2AirgapTqAllwdMax
      Em1AirgapTqAllwdMax: nonqueued-receiver-com-spec{data-element=TqMaxValSts, filter=data-filter-type=ALWAYS, init-value=fields=[0 Nm, 0 Nm]}, required-interface=Em1AirgapTqAllwdMax
      Em1AirgapTqAllwdMin: nonqueued-receiver-com-spec{data-element=TqMinValSts, filter=data-filter-type=ALWAYS, init-value=fields=[0 Nm, 0 Nm]}, required-interface=Em1AirgapTqAllwdMin
      DcDcCnvrPwrLossEstimdMax: required-interface=DcDcCnvrPwrLossEstimdMax
        required-com-specs:
          data-element=PwrValQf, filter=data-filter-type=ALWAYS, init-value=0
          data-element=PwrVal, filter=data-filter-type=ALWAYS, init-value=0 Watt
      DcDcCnvrPwrLossEstimdMin: required-interface=DcDcCnvrPwrLossEstimdMin
        required-com-specs:
          data-element=PwrValQf, filter=data-filter-type=ALWAYS, init-value=0
          data-element=PwrVal, filter=data-filter-type=ALWAYS, init-value=0 Watt
    provide port DclnkILim: provided-interface=DclnkILim
      provided-com-specs:
        data-element=IMinValSts, init-value=fields=[0 Ampere, 0 Ampere]
        data-element=IMaxValSts, init-value=fields=[0 Ampere, 0 Ampere]
    require port DcLnkUTarUCtrl: required-interface=DcLnkUTarUCtrl
      required-com-specs:
        data-element=UVal, filter=data-filter-type=ALWAYS, init-value=0 Volt
        data-element=UQf, filter=data-filter-type=ALWAYS, init-value=0
    require port ReqActvDchaSy: nonqueued-receiver-com-spec{data-element=FlgVal, filter=data-filter-type=ALWAYS, init-value=0 State}, required-interface=ReqActvDchaSy
    provide port Eds1CtrlModActQm: nonqueued-sender-com-spec{data-element=ModVal, init-value=0}, provided-interface=Eds1CtrlModActQm
    provide port Eds2CtrlModActQm: nonqueued-sender-com-spec{data-element=ModVal, init-value=0}, provided-interface=Eds2CtrlModActQm
    require port VehVAct: required-interface=VehVAct
      required-com-specs:
        data-element=QBit, filter=data-filter-type=ALWAYS, init-value=0
        data-element=VVal, filter=data-filter-type=ALWAYS, init-value=0 kmph
        data-element=ValSts, init-value=fields=[0 kmph, 0]
    provide port InsMonError: nonqueued-sender-com-spec{data-element=StsVal, init-value=1 State}, provided-interface=InsMonError
    require port ActiveReactions: nonqueued-receiver-com-spec{data-element=Status, filter=data-filter-type=ALWAYS, init-value=0}, required-interface=ActiveReactions
    5 x provide port:
      Asw1msEvents: nonqueued-sender-com-spec{data-element=Status, init-value=20 x 255}, provided-interface=Asw1msEvents
      Asw250msEvents: nonqueued-sender-com-spec{data-element=Status, init-value=23 x 255}, provided-interface=Asw250msEvents
      Em2SpdAbs: nonqueued-sender-com-spec{data-element=PECInIf_nAbs_VW, init-value=0}, provided-interface=PECInIf_nAbs_VW
      PECInIf_tqMax_VW: nonqueued-sender-com-spec{data-element=PECInIf_tqMax_VW, init-value=0}, provided-interface=PECInIf_tqMax_VW
      PECInIf_tqMin_VW: nonqueued-sender-com-spec{data-element=PECInIf_tqMin_VW, init-value=0}, provided-interface=PECInIf_tqMin_VW
    require port Em1PwrStModeAct: nonqueued-receiver-com-spec{data-element=ModVal, filter=data-filter-type=ALWAYS, init-value=0}, required-interface=Em1PwrStModeAct
    require port Em2PwrStModeAct: nonqueued-receiver-com-spec{data-element=ModVal, filter=data-filter-type=ALWAYS, init-value=0}, required-interface=Em2PwrStModeAct
    provide port Em1BattShutDwn: nonqueued-sender-com-spec{data-element=StsVal, init-value=0}, provided-interface=Em1BattShutDwn
    require port Eds1AirgapTqReq: nonqueued-receiver-com-spec{data-element=FlgVal, filter=data-filter-type=ALWAYS, init-value=0}, required-interface=Eds1AirgapTqReq
    13 x provide port:
      Em2BattShutDwn: nonqueued-sender-com-spec{data-element=StsVal, init-value=0}, provided-interface=Em2BattShutDwn
      Em1AscErrorReaction: nonqueued-sender-com-spec{data-element=StsVal, init-value=0}, provided-interface=Em1AscErrorReaction
      Em2AscErrorReaction: nonqueued-sender-com-spec{data-element=StsVal, init-value=0}, provided-interface=Em2AscErrorReaction
      Em1FwErrorReaction: nonqueued-sender-com-spec{data-element=StsVal, init-value=0}, provided-interface=Em1FwErrorReaction
      Em2FwErrorReaction: nonqueued-sender-com-spec{data-element=StsVal, init-value=0}, provided-interface=Em2FwErrorReaction
      Em1AirgapTqEstimdQm: provided-com-specs=[{data-element=TqVal, init-value=0 Nm}, {data-element=TqQf, init-value=0}], provided-interface=Em1AirgapTqEstimdQm
      Em2AirgapTqEstimdQm: provided-com-specs=[{data-element=TqVal, init-value=0 Nm}, {data-element=TqQf, init-value=0}], provided-interface=Em2AirgapTqEstimdQm
      Eds1PwrPerformanceIndcr: nonqueued-sender-com-spec{data-element=PwrIndcrValSts, init-value=fields=[0 Percent, 0 Percent]}, provided-interface=Eds1PwrPerformanceIndcr
      Eds1TempPerformanceIndcr: nonqueued-sender-com-spec{data-element=TempIndcrValSts, init-value=fields=[0 Percent, 0 Percent]}, provided-interface=Eds1TempPerformanceIndcr
      Eds1TqPerformanceIndcr: nonqueued-sender-com-spec{data-element=TqIndcrValSts, init-value=fields=[0 Percent, 0 Percent]}, provided-interface=Eds1TqPerformanceIndcr
      Eds2PwrPerformanceIndcr: nonqueued-sender-com-spec{data-element=PwrIndcrValSts, init-value=fields=[0 Percent, 0 Percent]}, provided-interface=Eds2PwrPerformanceIndcr
      Eds2TempPerformanceIndcr: nonqueued-sender-com-spec{data-element=TempIndcrValSts, init-value=fields=[0 Percent, 0 Percent]}, provided-interface=Eds2TempPerformanceIndcr
      Eds2TqPerformanceIndcr: nonqueued-sender-com-spec{data-element=TqIndcrValSts, init-value=fields=[0 Percent, 0 Percent]}, provided-interface=Eds2TqPerformanceIndcr
    require port Eds2TempPerformanceIndcrPe: required-interface=Eds2TempPerformanceIndcrPe
      required-com-specs:
        data-element=TempIndcrValSts, filter=data-filter-type=ALWAYS, init-value=fields=[0 Percent, 0 Percent]
        data-element=TempIndcrVal, filter=data-filter-type=ALWAYS, init-value=0 Percent
    require port Eds1TempPerformanceIndcrPe: required-interface=Eds1TempPerformanceIndcrPe
      required-com-specs:
        data-element=TempIndcrValSts, filter=data-filter-type=ALWAYS, init-value=fields=[0 Percent, 0 Percent]
        data-element=TempIndcrVal, filter=data-filter-type=ALWAYS, init-value=0 Percent
    4 x provide port:
      Asw10msEvents: nonqueued-sender-com-spec{data-element=Status, init-value=36 x 255}, provided-interface=Asw10msEvents
      HeatExWtrCooltOutlT: nonqueued-sender-com-spec{data-element=TValSts, init-value=fields=[20 degC, 0 degC]}, provided-interface=HeatExWtrCooltOutlT
      DcDcCnvrPwrMax: nonqueued-sender-com-spec{data-element=ValSts, init-value=fields=[0 W, 0]}, provided-interface=DcDcCnvrPwrMax
      DcLnkVoltFild: nonqueued-sender-com-spec{data-element=DcLnkVSts, init-value=fields=[0 V, 0 V]}, provided-interface=DcLnkVoltFild
    require port Clamp15: nonqueued-receiver-com-spec{data-element=ValSts, filter=data-filter-type=ALWAYS, init-value=fields=[0, 0]}, required-interface=Clamp15
    require port SopcStatus: nonqueued-receiver-com-spec{data-element=Val, filter=data-filter-type=ALWAYS, init-value=0}, required-interface=SopcStatus
    5 x provide port, all with nonqueued-sender-com-spec{data-element=Val, init-value=0}:
      SopcPermission: provided-interface=SopcPermission
      Em1RtmWarnTempEm: provided-interface=Em1RtmWarnTempEm
      Em1RtmWarnTempPwr: provided-interface=Em1RtmWarnTempPwr
      Em2RtmWarnTempEm: provided-interface=Em2RtmWarnTempEm
      Em2RtmWarnTempPwr: provided-interface=Em2RtmWarnTempPwr
    require port ActiveReactionsExtended: nonqueued-receiver-com-spec{data-element=Status, filter=data-filter-type=ALWAYS, init-value=[0, 0]}, required-interface=ActiveReactionsExtended
    provide port ASW_EDS_TQ250_Nvmdrv: nonqueued-sender-com-spec{data-element=TValArray, init-value=82 x 0}, provided-interface=ASW_EDS_TQ250_Nvmdrv
    5 x require port:
      Nvmdrv_ASW_EDS_TQ250: required-interface=Nvmdrv_ASW_EDS_TQ250
        required-com-specs:
          data-element=TValArray, filter=data-filter-type=ALWAYS, init-value=82 x 0
          data-element=NvmSts, filter=data-filter-type=ALWAYS, init-value=0
      RP_UnlockTorqueControl: nonqueued-receiver-com-spec{data-element=Sts, filter=data-filter-type=ALWAYS}, required-interface=UnlockTorqueControl
      LvDcUSw: nonqueued-receiver-com-spec{data-element=ValSts, filter=data-filter-type=ALWAYS, init-value=fields=[0 V, 0]}, required-interface=LvDcUSw
      Em1OffsLrng: required-interface=Em1OffsLrng
        required-com-specs:
          data-element=Cmpl, filter=data-filter-type=ALWAYS, init-value=0
          data-element=Req, filter=data-filter-type=ALWAYS, init-value=0
      Em2OffsLrng: required-interface=Em2OffsLrng
        required-com-specs:
          data-element=Cmpl, filter=data-filter-type=ALWAYS, init-value=0
          data-element=Req, filter=data-filter-type=ALWAYS, init-value=0
    provide port DcDcCnvrPwrMin: nonqueued-sender-com-spec{data-element=ValSts, init-value=fields=[0 W, 0]}, provided-interface=DcDcCnvrPwrMin
    provide port DcConnectorPwr: nonqueued-sender-com-spec{data-element=ValSts, init-value=fields=[8190 W, 0 W]}, provided-interface=DcConnectorPwr
    require port Em1ActvDchaSrcErr: required-interface=Em1ActvDchaSrcErr
      required-com-specs:
        data-element=StsVal, filter=data-filter-type=ALWAYS, init-value=0 B
        data-element=ErrSts, filter=data-filter-type=ALWAYS, init-value=0 B
    require port TempPerformanceIndcrDcDc: required-interface=TempPerformanceIndcrDcDc
      required-com-specs:
        data-element=TempIndcrValSts, filter=data-filter-type=ALWAYS, init-value=fields=[0 Percent, 0 Percent]
        data-element=TempIndcrVal, filter=data-filter-type=ALWAYS, init-value=0 Percent
    provide port Pe1Energies: nonqueued-sender-com-spec=data-element=Val, provided-interface=Pe1Energies
    provide port Pe2Energies: nonqueued-sender-com-spec=data-element=Val, provided-interface=Pe2Energies
    provide port DcConnectorILimDcDcPwr: nonqueued-sender-com-spec{data-element=ValSts, init-value=fields=[0 A, 0]}, provided-interface=DcConnectorILimDcDcPwr
    require port DcDcCnvrPwrLossLim: nonqueued-receiver-com-spec{data-element=PwrValSts, filter=data-filter-type=ALWAYS, init-value=fields=[0 W, 0]}, required-interface=DcDcCnvrPwrLossLim
    provide port Em1StatorWindgTEstimd: nonqueued-sender-com-spec{data-element=TValSts, init-value=fields=[0 degC, 0 degC]}, provided-interface=Em1StatorWindgTEstimd
    provide port Em2StatorWindgTEstimd: nonqueued-sender-com-spec{data-element=TValSts, init-value=fields=[0 degC, 0 degC]}, provided-interface=Em2StatorWindgTEstimd
    provide port DcConnectorILimMinDcDcPwr: nonqueued-sender-com-spec{data-element=ValSts, init-value=fields=[0 A, 0]}, provided-interface=DcConnectorILimMinDcDcPwr
    9 x require port:
      DcDcCnvrPwrLossLimMin: nonqueued-receiver-com-spec{data-element=PwrValSts, filter=data-filter-type=ALWAYS, init-value=fields=[0 W, 0]}, required-interface=DcDcCnvrPwrLossLimMin
      PcbSensTemp: nonqueued-receiver-com-spec{data-element=ValSts, filter=data-filter-type=ALWAYS, init-value=fields=[0 degC, 0 degC]}, required-interface=PcbSensTemp
      FCapSensTemp: required-interface=FCapSensTemp
        required-com-specs:
          data-element=ValSts, filter=data-filter-type=ALWAYS, init-value=fields=[0 degC, 0 degC]
          data-element=Val, filter=data-filter-type=ALWAYS, init-value=0 degC
      Clutch: nonqueued-receiver-com-spec{data-element=Sts, filter=data-filter-type=ALWAYS, init-value=0}, required-interface=Clutch
      CbSensTemp: nonqueued-receiver-com-spec{data-element=ValSts, filter=data-filter-type=ALWAYS, init-value=fields=[0 degC, 0]}, required-interface=CbSensTemp
      PbSensTemp: nonqueued-receiver-com-spec{data-element=ValSts, filter=data-filter-type=ALWAYS, init-value=fields=[0 degC, 0]}, required-interface=PbSensTemp
      Pe1IgbtTEstimd: nonqueued-receiver-com-spec{data-element=ValSts, filter=data-filter-type=ALWAYS, init-value=fields=[0 degC, 0 degC]}, required-interface=Pe1IgbtTEstimd
      Pe2IgbtTEstimd: nonqueued-receiver-com-spec{data-element=ValSts, filter=data-filter-type=ALWAYS, init-value=fields=[0 degC, 0 degC]}, required-interface=Pe2IgbtTEstimd
      DcLinkIAct: nonqueued-receiver-com-spec{data-element=ValSts, filter=data-filter-type=ALWAYS, init-value=fields=[0 A, 0 A]}, required-interface=DcLinkIAct
    provide port NDCPe1AcBusbarTEstimd: nonqueued-sender-com-spec{data-element=ValSts, init-value=fields=[20 degC, 20 degC, 20 degC, 0 degC]}, provided-interface=NDCPe1AcBusbarTEstimd
    provide port NDCPe2AcBusbarTEstimd: nonqueued-sender-com-spec{data-element=ValSts, init-value=fields=[20 degC, 20 degC, 20 degC, 0 degC]}, provided-interface=NDCPe2AcBusbarTEstimd
    provide port DclnkILimMinDcDcPwr: nonqueued-sender-com-spec{data-element=ValSts, init-value=fields=[0 A, 0 A]}, provided-interface=DclnkILimMinDcDcPwr
    4 x require port:
      DclnkUCtrlDeviation: nonqueued-receiver-com-spec{data-element=Val, filter=data-filter-type=ALWAYS, init-value=0 V}, required-interface=DclnkUCtrlDeviation
      DcDcCnvrPwrLossEstimd: required-interface=DcDcCnvrPwrLossEstimd
        required-com-specs:
          data-element=PwrValSts, filter=data-filter-type=ALWAYS, init-value=fields=[0 W, 0]
          data-element=PwrValQf, filter=data-filter-type=ALWAYS, init-value=0
          data-element=PwrVal, filter=data-filter-type=ALWAYS, init-value=0 W
      DcDcReac1TSw: nonqueued-receiver-com-spec{data-element=ValSts, handle-out-of-range=DEFAULT, filter=data-filter-type=ALWAYS, init-value=fields=[0 degC, 0 degC]}, required-interface=DcDcReac1TSw
      DcDcReac2TSw: nonqueued-receiver-com-spec{data-element=ValSts, handle-out-of-range=DEFAULT, filter=data-filter-type=ALWAYS, init-value=fields=[0 degC, 0 degC]}, required-interface=DcDcReac2TSw
    provide port Em1RotorMagnTEstimd: nonqueued-sender-com-spec=TMaxVal, provided-interface=Em1RotorMagnTEstimd
    provide port Em2RotorMagnTEstimd: nonqueued-sender-com-spec=TMaxVal, provided-interface=Em2RotorMagnTEstimd
    7 x require port:
      Em2AscRequest: nonqueued-receiver-com-spec{data-element=Val, filter=data-filter-type=ALWAYS, init-value=0}, required-interface=Em2AscRequest
      Em1AscRequest: nonqueued-receiver-com-spec{data-element=Val, filter=data-filter-type=ALWAYS, init-value=0}, required-interface=Em1AscRequest
      NvmDrvInit: nonqueued-receiver-com-spec{data-element=Sts, filter=data-filter-type=ALWAYS, init-value=0}, required-interface=NvmDrvInit
      Em1EffDegrLoadMin: nonqueued-receiver-com-spec{data-element=Val, filter=data-filter-type=ALWAYS, init-value=0}, required-interface=Em1EffDegrLoadMin
      IGBTMgrSy_NvmDrvSy: nonqueued-receiver-com-spec{data-element=SopcResultCounters, filter=data-filter-type=ALWAYS, init-value=12 x 0}, required-interface=IGBTMgrSy_NvmDrvSy
      EmStopTriggered: nonqueued-receiver-com-spec{data-element=Sts, filter=data-filter-type=ALWAYS, init-value=0}, required-interface=EmStopTriggered
      PeWtrCooltInletTEstimd: nonqueued-receiver-com-spec{data-element=ValSts, filter=data-filter-type=ALWAYS, init-value=fields=[20 degC, 0 degC]}, required-interface=PeWtrCooltInletTEstimd
    provide port AswExit: nonqueued-sender-com-spec{data-element=Sts, init-value=0}, provided-interface=AswExit
    6 x require port:
      InsMonReadyForShutdown: nonqueued-receiver-com-spec{data-element=FlgVal, filter=data-filter-type=ALWAYS, init-value=0}, required-interface=InsMonReadyForShutdown
      InsMonUDcLinkFreezeReq: nonqueued-receiver-com-spec{data-element=FlgVal, filter=data-filter-type=ALWAYS, init-value=0}, required-interface=InsMonUDcLinkFreezeReq
      FaultLatchSig: nonqueued-receiver-com-spec{data-element=Val, filter=data-filter-type=ALWAYS, init-value=0}, required-interface=FaultLatchSig
      Pe2FCapHotSpotTemp: required-interface=Pe2FCapHotSpotTemp
        required-com-specs:
          data-element=ValSts, filter=data-filter-type=ALWAYS, init-value=fields=[New:0, Status:0]
          data-element=Val
      Pe1FCapHotSpotTemp: required-interface=Pe1FCapHotSpotTemp
        required-com-specs:
          data-element=ValSts, filter=data-filter-type=ALWAYS, init-value=fields=[New:0, Status:0]
          data-element=Val
      EngCooltTQBit: nonqueued-receiver-com-spec{data-element=ValSts, filter=data-filter-type=ALWAYS, init-value=fields=[New:0, Status:0]}, required-interface=EngCooltTQBit
    provide port Em1StatorSurfaceTMax: nonqueued-sender-com-spec{data-element=ValSts, init-value=fields=[0 degC, 0 degC]}, provided-interface=Em1StatorSurfaceTMax
    provide port Em2StatorSurfaceTMax: nonqueued-sender-com-spec{data-element=ValSts, init-value=fields=[0 degC, 0 degC]}, provided-interface=Em2StatorSurfaceTMax
    6 x require port:
      InsMonPostRunCmplNvm: nonqueued-receiver-com-spec{data-element=Val, filter=data-filter-type=ALWAYS, init-value=0}, required-interface=InsMonPostRunCmplNvm
      PECOutIf_stSpdlCtl_VW: nonqueued-receiver-com-spec{data-element=PECOutIf_stSpdlCtl_VW, filter=data-filter-type=ALWAYS, init-value=0}, required-interface=PECOutIf_stSpdlCtl_VW
      PECInIf_cirmWhl_VW: nonqueued-receiver-com-spec{data-element=PECInIf_cirmWhl_VW, filter=data-filter-type=ALWAYS, init-value=0}, required-interface=PECInIf_cirmWhl_VW
      HighVoltageSftyActvReactn: nonqueued-receiver-com-spec{data-element=FlgVal, filter=data-filter-type=ALWAYS, init-value=0}, required-interface=HighVoltageSftyActvReactn
      HsmLifeCycleState: nonqueued-receiver-com-spec{data-element=Val, filter=data-filter-type=ALWAYS, init-value=0}, required-interface=HsmLifeCycleState
      WtrCooltInlTAct: nonqueued-receiver-com-spec{data-element=TVal, filter=data-filter-type=ALWAYS}, required-interface=WtrCooltInlTAct
    behavior ASW_EDS_TQ250_InternalBehavior: data-type-mapping=[BswMModeMapping, ApplMappingSet, DataTypeMappingSets, DataTypeMappingSet], handle-termination-and-restart=NO-SUPPORT
      exclusive area ExclusiveArea
      ar-typed-per-instance-memorys:
        data EolNvBlock_RamMirror: sw-calibration-access=READ-ONLY, type=Asw_EolNvBlockType
        data FastNvBlock_RamMirror: sw-calibration-access=READ-ONLY, type=Asw_FastNvBlockType
        data SafeNvBlock_RamMirror: sw-calibration-access=READ-ONLY, type=Asw_SafeNvBlockType
      swc mode switch event ModeSwitchedPrpShutdown: start-on-event=ExecExitAsw_Veh, activation=ON-ENTRY, mode=ModeSwitchPort_BSWM_COMBINEDACTION_BswMMode_PortInterfaces_BswMMode.CurrentMode.INTGR_BSWM_PRP_SHUTDOWN
      5 x timing event:
        TMT_Exec100msAsw_Veh: start-on-event=Exec100msAsw_Veh, period=0.1
          disabled-mode:
            ModeSwitchPort_BSWM_COMBINEDACTION_BswMMode_PortInterfaces_BswMMode.CurrentMode.INTGR_BSWM_STARTUP_TWO_CORE1_PHASE1
            ModeSwitchPort_BSWM_COMBINEDACTION_BswMMode_PortInterfaces_BswMMode.CurrentMode.INTGR_BSWM_GO_OFF_ONE_CORE0_PHASE1
            ModeSwitchPort_BSWM_COMBINEDACTION_BswMMode_PortInterfaces_BswMMode.CurrentMode.INTGR_BSWM_WAKEUP_TWO
            ModeSwitchPort_BSWM_COMBINEDACTION_BswMMode_PortInterfaces_BswMMode.CurrentMode.INTGR_BSWM_GO_OFF_ONE_CORE1_PHASE1
            ModeSwitchPort_BSWM_COMBINEDACTION_BswMMode_PortInterfaces_BswMMode.CurrentMode.INTGR_BSWM_GO_OFF_ONE_CORE0_PHASE2
            ModeSwitchPort_BSWM_COMBINEDACTION_BswMMode_PortInterfaces_BswMMode.CurrentMode.INTGR_BSWM_STARTUP_TWO_CORE0_PHASE2
            ModeSwitchPort_BSWM_COMBINEDACTION_BswMMode_PortInterfaces_BswMMode.CurrentMode.INTGR_BSWM_PRP_SHUTDOWN
            ModeSwitchPort_BSWM_COMBINEDACTION_BswMMode_PortInterfaces_BswMMode.CurrentMode.INTGR_BSWM_GO_OFF_ONE_CORE1_PHASE2
            ModeSwitchPort_BSWM_COMBINEDACTION_BswMMode_PortInterfaces_BswMMode.CurrentMode.INTGR_BSWM_STARTUP_TWO_CORE1_PHASE2
            ModeSwitchPort_BSWM_COMBINEDACTION_BswMMode_PortInterfaces_BswMMode.CurrentMode.INTGR_BSWM_STARTUP_TWO_CORE0_PHASE1
            ModeSwitchPort_BSWM_COMBINEDACTION_BswMMode_PortInterfaces_BswMMode.CurrentMode.INTGR_BSWM_STARTUP_TWO_CORE3_PHASE2
            ModeSwitchPort_BSWM_COMBINEDACTION_BswMMode_PortInterfaces_BswMMode.CurrentMode.INTGR_BSWM_GO_OFF_ONE_CORE2_PHASE1
            ModeSwitchPort_BSWM_COMBINEDACTION_BswMMode_PortInterfaces_BswMMode.CurrentMode.INTGR_BSWM_STARTUP_TWO_CORE2_PHASE1
            ModeSwitchPort_BSWM_COMBINEDACTION_BswMMode_PortInterfaces_BswMMode.CurrentMode.INTGR_BSWM_PRP_JUMP_BOOT_SHUTDOWN
            ModeSwitchPort_BSWM_COMBINEDACTION_BswMMode_PortInterfaces_BswMMode.CurrentMode.INTGR_BSWM_STARTUP_TWO_CORE3_PHASE1
            ModeSwitchPort_BSWM_COMBINEDACTION_BswMMode_PortInterfaces_BswMMode.CurrentMode.INTGR_BSWM_GO_OFF_ONE_CORE3_PHASE1
            ModeSwitchPort_BSWM_COMBINEDACTION_BswMMode_PortInterfaces_BswMMode.CurrentMode.INTGR_BSWM_GO_OFF_ONE_CORE2_PHASE2
            ModeSwitchPort_BSWM_COMBINEDACTION_BswMMode_PortInterfaces_BswMMode.CurrentMode.INTGR_BSWM_STARTUP_TWO_CORE2_PHASE2
            ModeSwitchPort_BSWM_COMBINEDACTION_BswMMode_PortInterfaces_BswMMode.CurrentMode.INTGR_BSWM_GO_OFF_ONE_CORE3_PHASE2
        TMT_Exec10msAsw_Veh: start-on-event=Exec10msAsw_Veh, period=0.01
          disabled-mode:
            ModeSwitchPort_BSWM_COMBINEDACTION_BswMMode_PortInterfaces_BswMMode.CurrentMode.INTGR_BSWM_STARTUP_TWO_CORE1_PHASE2
            ModeSwitchPort_BSWM_COMBINEDACTION_BswMMode_PortInterfaces_BswMMode.CurrentMode.INTGR_BSWM_STARTUP_TWO_CORE1_PHASE1
            ModeSwitchPort_BSWM_COMBINEDACTION_BswMMode_PortInterfaces_BswMMode.CurrentMode.INTGR_BSWM_GO_OFF_ONE_CORE0_PHASE2
            ModeSwitchPort_BSWM_COMBINEDACTION_BswMMode_PortInterfaces_BswMMode.CurrentMode.INTGR_BSWM_GO_OFF_ONE_CORE1_PHASE1
            ModeSwitchPort_BSWM_COMBINEDACTION_BswMMode_PortInterfaces_BswMMode.CurrentMode.INTGR_BSWM_PRP_SHUTDOWN
            ModeSwitchPort_BSWM_COMBINEDACTION_BswMMode_PortInterfaces_BswMMode.CurrentMode.INTGR_BSWM_STARTUP_TWO_CORE0_PHASE2
            ModeSwitchPort_BSWM_COMBINEDACTION_BswMMode_PortInterfaces_BswMMode.CurrentMode.INTGR_BSWM_STARTUP_TWO_CORE0_PHASE1
            ModeSwitchPort_BSWM_COMBINEDACTION_BswMMode_PortInterfaces_BswMMode.CurrentMode.INTGR_BSWM_GO_OFF_ONE_CORE0_PHASE1
            ModeSwitchPort_BSWM_COMBINEDACTION_BswMMode_PortInterfaces_BswMMode.CurrentMode.INTGR_BSWM_GO_OFF_ONE_CORE1_PHASE2
            ModeSwitchPort_BSWM_COMBINEDACTION_BswMMode_PortInterfaces_BswMMode.CurrentMode.INTGR_BSWM_WAKEUP_TWO
            ModeSwitchPort_BSWM_COMBINEDACTION_BswMMode_PortInterfaces_BswMMode.CurrentMode.INTGR_BSWM_GO_OFF_ONE_CORE3_PHASE1
            ModeSwitchPort_BSWM_COMBINEDACTION_BswMMode_PortInterfaces_BswMMode.CurrentMode.INTGR_BSWM_STARTUP_TWO_CORE2_PHASE1
            ModeSwitchPort_BSWM_COMBINEDACTION_BswMMode_PortInterfaces_BswMMode.CurrentMode.INTGR_BSWM_STARTUP_TWO_CORE3_PHASE1
            ModeSwitchPort_BSWM_COMBINEDACTION_BswMMode_PortInterfaces_BswMMode.CurrentMode.INTGR_BSWM_PRP_JUMP_BOOT_SHUTDOWN
            ModeSwitchPort_BSWM_COMBINEDACTION_BswMMode_PortInterfaces_BswMMode.CurrentMode.INTGR_BSWM_GO_OFF_ONE_CORE2_PHASE1
            ModeSwitchPort_BSWM_COMBINEDACTION_BswMMode_PortInterfaces_BswMMode.CurrentMode.INTGR_BSWM_STARTUP_TWO_CORE3_PHASE2
            ModeSwitchPort_BSWM_COMBINEDACTION_BswMMode_PortInterfaces_BswMMode.CurrentMode.INTGR_BSWM_GO_OFF_ONE_CORE3_PHASE2
            ModeSwitchPort_BSWM_COMBINEDACTION_BswMMode_PortInterfaces_BswMMode.CurrentMode.INTGR_BSWM_STARTUP_TWO_CORE2_PHASE2
            ModeSwitchPort_BSWM_COMBINEDACTION_BswMMode_PortInterfaces_BswMMode.CurrentMode.INTGR_BSWM_GO_OFF_ONE_CORE2_PHASE2
        TMT_Exec1msAsw_Veh: start-on-event=Exec1msAsw_Veh, period=0.001
          disabled-mode:
            ModeSwitchPort_BSWM_COMBINEDACTION_BswMMode_PortInterfaces_BswMMode.CurrentMode.INTGR_BSWM_GO_OFF_ONE_CORE1_PHASE1
            ModeSwitchPort_BSWM_COMBINEDACTION_BswMMode_PortInterfaces_BswMMode.CurrentMode.INTGR_BSWM_GO_OFF_ONE_CORE0_PHASE1
            ModeSwitchPort_BSWM_COMBINEDACTION_BswMMode_PortInterfaces_BswMMode.CurrentMode.INTGR_BSWM_STARTUP_TWO_CORE0_PHASE2
            ModeSwitchPort_BSWM_COMBINEDACTION_BswMMode_PortInterfaces_BswMMode.CurrentMode.INTGR_BSWM_STARTUP_TWO_CORE1_PHASE2
            ModeSwitchPort_BSWM_COMBINEDACTION_BswMMode_PortInterfaces_BswMMode.CurrentMode.INTGR_BSWM_GO_OFF_ONE_CORE1_PHASE2
            ModeSwitchPort_BSWM_COMBINEDACTION_BswMMode_PortInterfaces_BswMMode.CurrentMode.INTGR_BSWM_WAKEUP_TWO
            ModeSwitchPort_BSWM_COMBINEDACTION_BswMMode_PortInterfaces_BswMMode.CurrentMode.INTGR_BSWM_GO_OFF_ONE_CORE0_PHASE2
            ModeSwitchPort_BSWM_COMBINEDACTION_BswMMode_PortInterfaces_BswMMode.CurrentMode.INTGR_BSWM_STARTUP_TWO_CORE1_PHASE1
            ModeSwitchPort_BSWM_COMBINEDACTION_BswMMode_PortInterfaces_BswMMode.CurrentMode.INTGR_BSWM_STARTUP_TWO_CORE0_PHASE1
            ModeSwitchPort_BSWM_COMBINEDACTION_BswMMode_PortInterfaces_BswMMode.CurrentMode.INTGR_BSWM_PRP_SHUTDOWN
            ModeSwitchPort_BSWM_COMBINEDACTION_BswMMode_PortInterfaces_BswMMode.CurrentMode.INTGR_BSWM_STARTUP_TWO_CORE3_PHASE2
            ModeSwitchPort_BSWM_COMBINEDACTION_BswMMode_PortInterfaces_BswMMode.CurrentMode.INTGR_BSWM_PRP_JUMP_BOOT_SHUTDOWN
            ModeSwitchPort_BSWM_COMBINEDACTION_BswMMode_PortInterfaces_BswMMode.CurrentMode.INTGR_BSWM_GO_OFF_ONE_CORE3_PHASE1
            ModeSwitchPort_BSWM_COMBINEDACTION_BswMMode_PortInterfaces_BswMMode.CurrentMode.INTGR_BSWM_STARTUP_TWO_CORE3_PHASE1
            ModeSwitchPort_BSWM_COMBINEDACTION_BswMMode_PortInterfaces_BswMMode.CurrentMode.INTGR_BSWM_STARTUP_TWO_CORE2_PHASE1
            ModeSwitchPort_BSWM_COMBINEDACTION_BswMMode_PortInterfaces_BswMMode.CurrentMode.INTGR_BSWM_GO_OFF_ONE_CORE2_PHASE1
            ModeSwitchPort_BSWM_COMBINEDACTION_BswMMode_PortInterfaces_BswMMode.CurrentMode.INTGR_BSWM_STARTUP_TWO_CORE2_PHASE2
            ModeSwitchPort_BSWM_COMBINEDACTION_BswMMode_PortInterfaces_BswMMode.CurrentMode.INTGR_BSWM_GO_OFF_ONE_CORE2_PHASE2
            ModeSwitchPort_BSWM_COMBINEDACTION_BswMMode_PortInterfaces_BswMMode.CurrentMode.INTGR_BSWM_GO_OFF_ONE_CORE3_PHASE2
        TMT_Exec250msAsw_Veh: start-on-event=Exec250msAsw_Veh, period=0.25
          disabled-mode:
            ModeSwitchPort_BSWM_COMBINEDACTION_BswMMode_PortInterfaces_BswMMode.CurrentMode.INTGR_BSWM_WAKEUP_TWO
            ModeSwitchPort_BSWM_COMBINEDACTION_BswMMode_PortInterfaces_BswMMode.CurrentMode.INTGR_BSWM_STARTUP_TWO_CORE0_PHASE1
            ModeSwitchPort_BSWM_COMBINEDACTION_BswMMode_PortInterfaces_BswMMode.CurrentMode.INTGR_BSWM_GO_OFF_ONE_CORE0_PHASE1
            ModeSwitchPort_BSWM_COMBINEDACTION_BswMMode_PortInterfaces_BswMMode.CurrentMode.INTGR_BSWM_STARTUP_TWO_CORE1_PHASE2
            ModeSwitchPort_BSWM_COMBINEDACTION_BswMMode_PortInterfaces_BswMMode.CurrentMode.INTGR_BSWM_STARTUP_TWO_CORE1_PHASE1
            ModeSwitchPort_BSWM_COMBINEDACTION_BswMMode_PortInterfaces_BswMMode.CurrentMode.INTGR_BSWM_GO_OFF_ONE_CORE0_PHASE2
            ModeSwitchPort_BSWM_COMBINEDACTION_BswMMode_PortInterfaces_BswMMode.CurrentMode.INTGR_BSWM_STARTUP_TWO_CORE0_PHASE2
            ModeSwitchPort_BSWM_COMBINEDACTION_BswMMode_PortInterfaces_BswMMode.CurrentMode.INTGR_BSWM_PRP_SHUTDOWN
            ModeSwitchPort_BSWM_COMBINEDACTION_BswMMode_PortInterfaces_BswMMode.CurrentMode.INTGR_BSWM_GO_OFF_ONE_CORE1_PHASE1
            ModeSwitchPort_BSWM_COMBINEDACTION_BswMMode_PortInterfaces_BswMMode.CurrentMode.INTGR_BSWM_GO_OFF_ONE_CORE1_PHASE2
            ModeSwitchPort_BSWM_COMBINEDACTION_BswMMode_PortInterfaces_BswMMode.CurrentMode.INTGR_BSWM_STARTUP_TWO_CORE3_PHASE2
            ModeSwitchPort_BSWM_COMBINEDACTION_BswMMode_PortInterfaces_BswMMode.CurrentMode.INTGR_BSWM_GO_OFF_ONE_CORE3_PHASE1
            ModeSwitchPort_BSWM_COMBINEDACTION_BswMMode_PortInterfaces_BswMMode.CurrentMode.INTGR_BSWM_GO_OFF_ONE_CORE2_PHASE2
            ModeSwitchPort_BSWM_COMBINEDACTION_BswMMode_PortInterfaces_BswMMode.CurrentMode.INTGR_BSWM_STARTUP_TWO_CORE2_PHASE2
            ModeSwitchPort_BSWM_COMBINEDACTION_BswMMode_PortInterfaces_BswMMode.CurrentMode.INTGR_BSWM_GO_OFF_ONE_CORE3_PHASE2
            ModeSwitchPort_BSWM_COMBINEDACTION_BswMMode_PortInterfaces_BswMMode.CurrentMode.INTGR_BSWM_GO_OFF_ONE_CORE2_PHASE1
            ModeSwitchPort_BSWM_COMBINEDACTION_BswMMode_PortInterfaces_BswMMode.CurrentMode.INTGR_BSWM_STARTUP_TWO_CORE2_PHASE1
            ModeSwitchPort_BSWM_COMBINEDACTION_BswMMode_PortInterfaces_BswMMode.CurrentMode.INTGR_BSWM_PRP_JUMP_BOOT_SHUTDOWN
            ModeSwitchPort_BSWM_COMBINEDACTION_BswMMode_PortInterfaces_BswMMode.CurrentMode.INTGR_BSWM_STARTUP_TWO_CORE3_PHASE1
        TMT_Event_GetEventFailed: start-on-event=Event_GetEventFailed, period=0.1
      data received event DRT_ExecInitAsw_Veh_NvmDrvInit_Sts: start-on-event=ExecInitAsw_Veh, data=NvmDrvInit.Sts
      7 x runnable:
        Exec100msAsw_Veh
          data-send-points:
            access SEND_AswReadyForShutdown_FlgVal: accessed-variable=AswReadyForShutdown.FlgVal
            access SEND_InsMonError_StsVal: accessed-variable=InsMonError.StsVal
        Exec10msAsw_Veh: can-enter-exclusive-area=ExclusiveArea
          data-receive-point-by-arguments:
            48 x access:
              REC_Em1StatorAcBusbarHeatFlowPhaU_HeatFlowPhaUVal: accessed-variable=Em1StatorAcBusbarHeatFlowPhaU.HeatFlowPhaUVal
              REC_Em1StatorAcBusbarHeatFlowPhaU_HeatFlowPhaUValQf: accessed-variable=Em1StatorAcBusbarHeatFlowPhaU.HeatFlowPhaUValQf
              REC_Em1StatorAcBusbarHeatFlowPhaV_HeatFlowPhaVVal: accessed-variable=Em1StatorAcBusbarHeatFlowPhaV.HeatFlowPhaVVal
              REC_Em1StatorAcBusbarHeatFlowPhaV_HeatFlowPhaVValQf: accessed-variable=Em1StatorAcBusbarHeatFlowPhaV.HeatFlowPhaVValQf
              REC_Em1StatorAcBusbarHeatFlowPhaW_HeatFlowPhaWVal: accessed-variable=Em1StatorAcBusbarHeatFlowPhaW.HeatFlowPhaWVal
              REC_Em1StatorAcBusbarHeatFlowPhaW_HeatFlowPhaWValQf: accessed-variable=Em1StatorAcBusbarHeatFlowPhaW.HeatFlowPhaWValQf
              REC_Em2StatorAcBusbarHeatFlowPhaU_HeatFlowPhaUVal: accessed-variable=Em2StatorAcBusbarHeatFlowPhaU.HeatFlowPhaUVal
              REC_Em2StatorAcBusbarHeatFlowPhaU_HeatFlowPhaUValQf: accessed-variable=Em2StatorAcBusbarHeatFlowPhaU.HeatFlowPhaUValQf
              REC_Em2StatorAcBusbarHeatFlowPhaV_HeatFlowPhaVVal: accessed-variable=Em2StatorAcBusbarHeatFlowPhaV.HeatFlowPhaVVal
              REC_Em2StatorAcBusbarHeatFlowPhaV_HeatFlowPhaVValQf: accessed-variable=Em2StatorAcBusbarHeatFlowPhaV.HeatFlowPhaVValQf
              REC_Em2StatorAcBusbarHeatFlowPhaW_HeatFlowPhaWVal: accessed-variable=Em2StatorAcBusbarHeatFlowPhaW.HeatFlowPhaWVal
              REC_Em2StatorAcBusbarHeatFlowPhaW_HeatFlowPhaWValQf: accessed-variable=Em2StatorAcBusbarHeatFlowPhaW.HeatFlowPhaWValQf
              REC_Em1CurrMaxLim_IMaxVal: accessed-variable=Em1CurrMaxLim.IMaxVal
              REC_Em1CurrMinLim_IMinVal: accessed-variable=Em1CurrMinLim.IMinVal
              REC_Em1VoltMaxLim_UMaxVal: accessed-variable=Em1VoltMaxLim.UMaxVal
              REC_Em1VoltMinLim_UMinVal: accessed-variable=Em1VoltMinLim.UMinVal
              REC_Em2CurrMaxLim_IMaxVal: accessed-variable=Em2CurrMaxLim.IMaxVal
              REC_Em2CurrMinLim_IMinVal: accessed-variable=Em2CurrMinLim.IMinVal
              REC_Em2VoltMaxLim_UMaxVal: accessed-variable=Em2VoltMaxLim.UMaxVal
              REC_Em2VoltMinLim_UMinVal: accessed-variable=Em2VoltMinLim.UMinVal
              REC_Em2TqLimTracCtrl_TqMaxVal: accessed-variable=Em2TqLimTracCtrl.TqMaxVal
              REC_Em2TqLimTracCtrl_TqMinVal: accessed-variable=Em2TqLimTracCtrl.TqMinVal
              REC_ActiveReactions_Status: accessed-variable=ActiveReactions.Status
              REC_Eds1TempPerformanceIndcrPe_TempIndcrVal: accessed-variable=Eds1TempPerformanceIndcrPe.TempIndcrVal
              REC_Eds2TempPerformanceIndcrPe_TempIndcrVal: accessed-variable=Eds2TempPerformanceIndcrPe.TempIndcrVal
              REC_ActiveReactionsExtended_Status: accessed-variable=ActiveReactionsExtended.Status
              REC_Em1CurrMaxLim_IMaxValSts: accessed-variable=Em1CurrMaxLim.IMaxValSts
              REC_Em1CurrMinLim_IMinValSts: accessed-variable=Em1CurrMinLim.IMinValSts
              REC_Em1VoltMaxLim_UMaxValSts: accessed-variable=Em1VoltMaxLim.UMaxValSts
              REC_Em1VoltMinLim_UMinValSts: accessed-variable=Em1VoltMinLim.UMinValSts
              REC_Em2CurrMaxLim_IMaxValSts: accessed-variable=Em2CurrMaxLim.IMaxValSts
              REC_Em2CurrMinLim_IMinValSts: accessed-variable=Em2CurrMinLim.IMinValSts
              REC_Em2VoltMaxLim_UMaxValSts: accessed-variable=Em2VoltMaxLim.UMaxValSts
              REC_Em2VoltMinLim_UMinValSts: accessed-variable=Em2VoltMinLim.UMinValSts
              REC_TempPerformanceIndcrDcDc_TempIndcrValSts: accessed-variable=TempPerformanceIndcrDcDc.TempIndcrValSts
              REC_TempPerformanceIndcrDcDc_TempIndcrVal: accessed-variable=TempPerformanceIndcrDcDc.TempIndcrVal
              REC_Eds1TempPerformanceIndcrPe_TempIndcrValSts: accessed-variable=Eds1TempPerformanceIndcrPe.TempIndcrValSts
              REC_Eds2TempPerformanceIndcrPe_TempIndcrValSts: accessed-variable=Eds2TempPerformanceIndcrPe.TempIndcrValSts
              REC_DcDcCnvrPwrLossLim_PwrValSts: accessed-variable=DcDcCnvrPwrLossLim.PwrValSts
              REC_DcDcCnvrPwrLossLimMin_PwrValSts: accessed-variable=DcDcCnvrPwrLossLimMin.PwrValSts
              REC_Em1EffDegrLoadMin_Val: accessed-variable=Em1EffDegrLoadMin.Val
              REC_WtrCooltInlVolFlowAct_ValSts: accessed-variable=WtrCooltInlVolFlowAct.ValSts
              REC_Em1RotorPosnElec_PosnQf: accessed-variable=Em1RotorPosnElec.PosnQf
              REC_Em2RotorPosnElec_PosnQf: accessed-variable=Em2RotorPosnElec.PosnQf
              REC_DcDcCnvrPwrLossEstimd_PwrVal: accessed-variable=DcDcCnvrPwrLossEstimd.PwrVal
              REC_DcDcCnvrPwrLossEstimd_PwrValQf: accessed-variable=DcDcCnvrPwrLossEstimd.PwrValQf
              REC_VehVAct_ValSts: accessed-variable=VehVAct.ValSts
              REC_PECInIf_cirmWhl_VW_PECInIf_cirmWhl_VW: accessed-variable=PECInIf_cirmWhl_VW.PECInIf_cirmWhl_VW
          data-send-points:
            56 x access:
              SEND_EM1DetnFreeVolt_StsVal: accessed-variable=EM1DetnFreeVolt.StsVal
              SEND_EM1DetnOpenHVWire_StsVal: accessed-variable=EM1DetnOpenHVWire.StsVal
              SEND_EM2DetnFreeVolt_StsVal: accessed-variable=EM2DetnFreeVolt.StsVal
              SEND_EM2DetnOpenHVWire_StsVal: accessed-variable=EM2DetnOpenHVWire.StsVal
              SEND_InsMonError_StsVal: accessed-variable=InsMonError.StsVal
              SEND_Em1BattShutDwn_StsVal: accessed-variable=Em1BattShutDwn.StsVal
              SEND_Em2BattShutDwn_StsVal: accessed-variable=Em2BattShutDwn.StsVal
              SEND_Em1AscErrorReaction_StsVal: accessed-variable=Em1AscErrorReaction.StsVal
              SEND_Em1FwErrorReaction_StsVal: accessed-variable=Em1FwErrorReaction.StsVal
              SEND_Em2AscErrorReaction_StsVal: accessed-variable=Em2AscErrorReaction.StsVal
              SEND_Em2FwErrorReaction_StsVal: accessed-variable=Em2FwErrorReaction.StsVal
              SEND_Em1AirgapTqOver_FlgVal: accessed-variable=Em1AirgapTqOver.FlgVal
              SEND_Em2AirgapTqOver_FlgVal: accessed-variable=Em2AirgapTqOver.FlgVal
              SEND_Em1AirgapTqLimMax_TqMaxVal: accessed-variable=Em1AirgapTqLimMax.TqMaxVal
              SEND_Asw10msEvents_Status: accessed-variable=Asw10msEvents.Status
              SEND_Em1AirgapTqMax_TqMaxValSts: accessed-variable=Em1AirgapTqMax.TqMaxValSts
              SEND_Em1AirgapTqMin_TqMinValSts: accessed-variable=Em1AirgapTqMin.TqMinValSts
              SEND_Em1AirgapTqMinTot_TqMinValSts: accessed-variable=Em1AirgapTqMinTot.TqMinValSts
              SEND_Em1AirgapTqMaxTot_TqMaxValSts: accessed-variable=Em1AirgapTqMaxTot.TqMaxValSts
              SEND_Em2AirgapTqMinTot_TqMinValSts: accessed-variable=Em2AirgapTqMinTot.TqMinValSts
              SEND_Em2AirgapTqMaxTot_TqMaxValSts: accessed-variable=Em2AirgapTqMaxTot.TqMaxValSts
              SEND_Em1AirgapTqChartcMax_TqMaxValSts: accessed-variable=Em1AirgapTqChartcMax.TqMaxValSts
              SEND_Em2AirgapTqChartcMax_TqMaxValSts: accessed-variable=Em2AirgapTqChartcMax.TqMaxValSts
              SEND_Em1AirgapTqCpbyHi_TqValSts: accessed-variable=Em1AirgapTqCpbyHi.TqValSts
              SEND_Em2AirgapTqCpbyHi_TqValSts: accessed-variable=Em2AirgapTqCpbyHi.TqValSts
              SEND_Em1AirgapTqCpbyLo_TqValSts: accessed-variable=Em1AirgapTqCpbyLo.TqValSts
              SEND_Em2AirgapTqCpbyLo_TqValSts: accessed-variable=Em2AirgapTqCpbyLo.TqValSts
              SEND_Em2AirgapTqLimMax_TqMaxValSts: accessed-variable=Em2AirgapTqLimMax.TqMaxValSts
              SEND_Em1AirgapTqLimMin_TqMinValSts: accessed-variable=Em1AirgapTqLimMin.TqMinValSts
              SEND_Em2AirgapTqLimMin_TqMinValSts: accessed-variable=Em2AirgapTqLimMin.TqMinValSts
              SEND_Eds1PwrPerformanceIndcr_PwrIndcrValSts: accessed-variable=Eds1PwrPerformanceIndcr.PwrIndcrValSts
              SEND_Eds2PwrPerformanceIndcr_PwrIndcrValSts: accessed-variable=Eds2PwrPerformanceIndcr.PwrIndcrValSts
              SEND_Eds1TempPerformanceIndcr_TempIndcrValSts: accessed-variable=Eds1TempPerformanceIndcr.TempIndcrValSts
              SEND_Eds2TempPerformanceIndcr_TempIndcrValSts: accessed-variable=Eds2TempPerformanceIndcr.TempIndcrValSts
              SEND_Eds1TqPerformanceIndcr_TqIndcrValSts: accessed-variable=Eds1TqPerformanceIndcr.TqIndcrValSts
              SEND_Eds2TqPerformanceIndcr_TqIndcrValSts: accessed-variable=Eds2TqPerformanceIndcr.TqIndcrValSts
              SEND_Em2AirgapTqMax_TqMaxValSts: accessed-variable=Em2AirgapTqMax.TqMaxValSts
              SEND_Em2AirgapTqMin_TqMinValSts: accessed-variable=Em2AirgapTqMin.TqMinValSts
              SEND_Em1AirgapPwrChartcMax_PwrMaxValSts: accessed-variable=Em1AirgapPwrChartcMax.PwrMaxValSts
              SEND_Em2AirgapPwrChartcMax_PwrMaxValSts: accessed-variable=Em2AirgapPwrChartcMax.PwrMaxValSts
              SEND_Em1AirgapPwrCpbyHi_PwrValSts: accessed-variable=Em1AirgapPwrCpbyHi.PwrValSts
              SEND_Em1AirgapPwrCpbyLo_PwrValSts: accessed-variable=Em1AirgapPwrCpbyLo.PwrValSts
              SEND_Em2AirgapPwrCpbyHi_PwrValSts: accessed-variable=Em2AirgapPwrCpbyHi.PwrValSts
              SEND_Em2AirgapPwrCpbyLo_PwrValSts: accessed-variable=Em2AirgapPwrCpbyLo.PwrValSts
              SEND_DcDcCnvrPwrMin_ValSts: accessed-variable=DcDcCnvrPwrMin.ValSts
              SEND_Pe1Energies_Val: accessed-variable=Pe1Energies.Val
              SEND_Pe2Energies_Val: accessed-variable=Pe2Energies.Val
              SEND_Em1AirgapTqLimMax_TqMaxValSts: accessed-variable=Em1AirgapTqLimMax.TqMaxValSts
              SEND_DclnkILimMinDcDcPwr_ValSts: accessed-variable=DcConnectorILimMinDcDcPwr.ValSts
              SEND_DcConnectorILimMinDcDcPwr_ValSts: accessed-variable=DcConnectorILimMinDcDcPwr.ValSts
              SEND_DcConnectorILimDcDcPwr_ValSts: accessed-variable=DcConnectorILimDcDcPwr.ValSts
              SEND_DclnkILimMinDcDcPwr_ValSts_1: accessed-variable=DclnkILimMinDcDcPwr.ValSts
              SEND_Em1AirgapTqAddlGenr_TqQf: accessed-variable=Em1AirgapTqAddlGenr.TqQf
              SEND_Em1AirgapTqAddlGenr_TqVal: accessed-variable=Em1AirgapTqAddlGenr.TqVal
              SEND_Em1AirgapTqAddlGenr_TqValSts: accessed-variable=Em1AirgapTqAddlGenr.TqValSts
              SEND_Em2AirgapTqAddlGenr_TqValSts: accessed-variable=Em2AirgapTqAddlGenr.TqValSts
        Exec1msAsw_Veh: can-enter-exclusive-area=ExclusiveArea
          data-receive-point-by-arguments:
            123 x access:
              REC_ActvDchaActvt_FlgVal: accessed-variable=ActvDchaActvt.FlgVal
              REC_DcConnectorUSw_UVal: accessed-variable=DcConnectorUSw.UVal
              REC_Eds1CtrlModTar_ModVal: accessed-variable=Eds1CtrlModTar.ModVal
              REC_Em1IdqAct_IdQf: accessed-variable=Em1IdqAct.IdQf
              REC_Em1IdqAct_IdVal: accessed-variable=Em1IdqAct.IdVal
              REC_Em1IdqAct_IqQf: accessed-variable=Em1IdqAct.IqQf
              REC_Em1IdqAct_IqVal: accessed-variable=Em1IdqAct.IqVal
              REC_Em1UdqTar_UdVal: accessed-variable=Em1UdqTar.UdVal
              REC_Em1UdqTar_UqVal: accessed-variable=Em1UdqTar.UqVal
              REC_Em2IdqAct_IdQf: accessed-variable=Em2IdqAct.IdQf
              REC_Em2IdqAct_IdVal: accessed-variable=Em2IdqAct.IdVal
              REC_Em2IdqAct_IqQf: accessed-variable=Em2IdqAct.IqQf
              REC_Em2IdqAct_IqVal: accessed-variable=Em2IdqAct.IqVal
              REC_Em2UdqTar_UdVal: accessed-variable=Em2UdqTar.UdVal
              REC_Em2UdqTar_UqVal: accessed-variable=Em2UdqTar.UqVal
              REC_NDCDCDCCtrlSts_DCDCStatus: accessed-variable=NDCDCDCCtrlSts.DCDCStatus
              REC_NDCPe1CtrlCddCurr_IdcVal: accessed-variable=NDCPe1CtrlCddCurr.IdcVal
              REC_NDCPe2CtrlCddCurr_IdcVal: accessed-variable=NDCPe2CtrlCddCurr.IdcVal
              REC_Pe1ModlnMeth_ModlnMeth: accessed-variable=Pe1ModlnMeth.ModlnMeth
              REC_Pe1PwmFrqLim_FrqMaxVal: accessed-variable=Pe1PwmFrqLim.FrqMaxVal
              REC_Pe1PwmFrqLim_FrqMinVal: accessed-variable=Pe1PwmFrqLim.FrqMinVal
              REC_Pe1PwrLossEstimd_PwrVal: accessed-variable=Pe1PwrLossEstimd.PwrVal
              REC_Pe1PwrLossEstimd_PwrValQf: accessed-variable=Pe1PwrLossEstimd.PwrValQf
              REC_Pe1ThermDeratFac_MaxVal: accessed-variable=Pe1ThermDeratFac.MaxVal
              REC_Pe2ModlnMeth_ModlnMeth: accessed-variable=Pe2ModlnMeth.ModlnMeth
              REC_Pe2PwmFrqLim_FrqMaxVal: accessed-variable=Pe2PwmFrqLim.FrqMaxVal
              REC_Pe2PwmFrqLim_FrqMinVal: accessed-variable=Pe2PwmFrqLim.FrqMinVal
              REC_Pe2PwrLossEstimd_PwrVal: accessed-variable=Pe2PwrLossEstimd.PwrVal
              REC_Pe2PwrLossEstimd_PwrValQf: accessed-variable=Pe2PwrLossEstimd.PwrValQf
              REC_Pe2ThermDeratFac_MaxVal: accessed-variable=Pe2ThermDeratFac.MaxVal
              REC_PeDcDcCnvrTDeratFac_FacVal: accessed-variable=PeDcDcCnvrTDeratFac.FacVal
              REC_ToothNr_NrVal: accessed-variable=ToothNr.NrVal
              REC_Em2AirgapTqDampgSts_PECOutIf_bDampCtl_VW: accessed-variable=Em2AirgapTqDampgSts.PECOutIf_bDampCtl_VW
              REC_Em2AirgapTqLimLo_PECOutIf_tqSpSpdlMin_VW: accessed-variable=Em2AirgapTqLimLo.PECOutIf_tqSpSpdlMin_VW
              REC_Em2AirgapTqTarTot_PECOutIf_tqSp_VW: accessed-variable=Em2AirgapTqTarTot.PECOutIf_tqSp_VW
              REC_Pe1PhaIAcRmsSwPhaU_IVal: accessed-variable=Pe1PhaIAcRmsSwPhaU.IVal
              REC_Pe1PhaIAcRmsSwPhaV_IVal: accessed-variable=Pe1PhaIAcRmsSwPhaV.IVal
              REC_Pe1PhaIAcRmsSwPhaW_IVal: accessed-variable=Pe1PhaIAcRmsSwPhaW.IVal
              REC_Pe2PhaIAcRmsSwPhaU_IVal: accessed-variable=Pe2PhaIAcRmsSwPhaU.IVal
              REC_Pe2PhaIAcRmsSwPhaV_IVal: accessed-variable=Pe2PhaIAcRmsSwPhaV.IVal
              REC_Pe2PhaIAcRmsSwPhaW_IVal: accessed-variable=Pe2PhaIAcRmsSwPhaW.IVal
              REC_Em2AirgapTqTar_TqVal: accessed-variable=Em2AirgapTqTar.TqVal
              REC_Eds2CtrlModTar_ModVal: accessed-variable=Eds2CtrlModTar.ModVal
              REC_Em2TqLimTracCtrl_TqMaxVal: accessed-variable=Em2TqLimTracCtrl.TqMaxVal
              REC_Em2TqLimTracCtrl_TqMinVal: accessed-variable=Em2TqLimTracCtrl.TqMinVal
              REC_Em1SpdAct_SpdQf: accessed-variable=Em1SpdAct.SpdQf
              REC_Em1SpdAct_SpdVal: accessed-variable=Em1SpdAct.SpdVal
              REC_Em2SpdAct_SpdQf: accessed-variable=Em2SpdAct.SpdQf
              REC_Em2SpdAct_SpdVal: accessed-variable=Em2SpdAct.SpdVal
              REC_DcConnectorUSw_DcLnkVQf: accessed-variable=DcConnectorUSw.UQf
              REC_DcDcCnvrPwrLossEstimdMax_PwrVal: accessed-variable=DcDcCnvrPwrLossEstimdMax.PwrVal
              REC_DcDcCnvrPwrLossEstimdMax_PwrValQf: accessed-variable=DcDcCnvrPwrLossEstimdMax.PwrValQf
              REC_DcDcCnvrPwrLossEstimdMin_PwrVal: accessed-variable=DcDcCnvrPwrLossEstimdMin.PwrVal
              REC_DcDcCnvrPwrLossEstimdMin_PwrValQf: accessed-variable=DcDcCnvrPwrLossEstimdMin.PwrValQf
              REC_DcLnkUTarUCtrl_UQf: accessed-variable=DcLnkUTarUCtrl.UQf
              REC_DcLnkUTarUCtrl_Uval: accessed-variable=DcLnkUTarUCtrl.UVal
              REC_ReqActvDchaSy_FlgVal: accessed-variable=ReqActvDchaSy.FlgVal
              REC_VehVAct_VVal: accessed-variable=VehVAct.VVal
              REC_Em1PwrStModeAct_ModVal: accessed-variable=Em1PwrStModeAct.ModVal
              REC_Em2PwrStModeAct_ModVal: accessed-variable=Em2PwrStModeAct.ModVal
              REC_Eds1AirgapTqReq_FlgVal: accessed-variable=Eds1AirgapTqReq.FlgVal
              REC_RlySts_StsVal: accessed-variable=RlySts.StsVal
              REC_Clamp15_ValSts: accessed-variable=Clamp15.ValSts
              REC_DcLnkUAct_ValSts: accessed-variable=DcLnkUAct.ValSts
              REC_DcConnectorISw_ValSts: accessed-variable=DcConnectorISw.ValSts
              REC_Em1StatorWindgTSw_TValSts: accessed-variable=Em1StatorWindgTSw.TValSts
              REC_Em2StatorWindgTSw_TValSts: accessed-variable=Em2StatorWindgTSw.TValSts
              REC_SopcStatus_Val: accessed-variable=SopcStatus.Val
              REC_Em1AirgapTqTar_TqValSts: accessed-variable=Em1AirgapTqTar.TqValSts
              REC_OilCooltTSw_TValSts: accessed-variable=OilCooltTSw.TValSts
              REC_VehTiOff_TiValSts: accessed-variable=VehTiOff.TiValSts
              REC_DcConnectorULim_UMaxValSts: accessed-variable=DcConnectorULim.UMaxValSts
              REC_DcConnectorULim_UMinValSts: accessed-variable=DcConnectorULim.UMinValSts
              REC_DcConnectorILim_MaxIValSts: accessed-variable=DcConnectorILim.MaxIValSts
              REC_DcConnectorILim_MinIValSts: accessed-variable=DcConnectorILim.MinIValSts
              REC_Eds1GenPwr_PwrValSts: accessed-variable=Eds1GenPwr.PwrValSts
              REC_Eds1MaxPwr_PwrValSts: accessed-variable=Eds1MaxPwr.PwrValSts
              REC_Eds1MaxPwrTot_PwrValSts: accessed-variable=Eds1MaxPwrTot.PwrValSts
              REC_Eds1MinPwr_PwrValSts: accessed-variable=Eds1MinPwr.PwrValSts
              REC_Eds1MinPwrTot_PwrValSts: accessed-variable=Eds1MinPwrTot.PwrValSts
              REC_Eds2GenPwr_PwrValSts: accessed-variable=Eds2GenPwr.PwrValSts
              REC_Eds2MaxPwr_PwrValSts: accessed-variable=Eds2MaxPwr.PwrValSts
              REC_Eds2MaxPwrTot_PwrValSts: accessed-variable=Eds2MaxPwrTot.PwrValSts
              REC_Eds2MinPwr_PwrValSts: accessed-variable=Eds2MinPwr.PwrValSts
              REC_Eds2MinPwrTot_PwrValSts: accessed-variable=Eds2MinPwrTot.PwrValSts
              REC_Em1AirgapTqAllwdMax_TqMaxValSts: accessed-variable=Em1AirgapTqAllwdMax.TqMaxValSts
              REC_Em1AirgapTqAllwdMin_TqMinValSts: accessed-variable=Em1AirgapTqAllwdMin.TqMinValSts
              REC_Em2AirgapTqAllwdMax_TqMaxValSts: accessed-variable=Em2AirgapTqAllwdMax.TqMaxValSts
              REC_Em2AirgapTqAllwdMin_TqMinValSts: accessed-variable=Em2AirgapTqAllwdMin.TqMinValSts
              REC_RP_UnlockTorqueControl_Sts: accessed-variable=RP_UnlockTorqueControl.Sts
              REC_LvDcUSw_ValSts: accessed-variable=LvDcUSw.ValSts
              REC_Em1OffsLrng_Cmpl: accessed-variable=Em1OffsLrng.Cmpl
              REC_Em1OffsLrng_Req: accessed-variable=Em1OffsLrng.Req
              REC_Em2OffsLrng_Cmpl: accessed-variable=Em2OffsLrng.Cmpl
              REC_Em2OffsLrng_Req: accessed-variable=Em2OffsLrng.Req
              REC_Em2AirgapTqTar_TqValSts: accessed-variable=Em2AirgapTqTar.TqValSts
              REC_Em1ActvDchaSrcErr_StsVal: accessed-variable=Em1ActvDchaSrcErr.StsVal
              REC_NDCPe1CtrlCddCurr_IdcValSts: accessed-variable=NDCPe1CtrlCddCurr.IdcValSts
              REC_NDCPe2CtrlCddCurr_IdcValSts: accessed-variable=NDCPe2CtrlCddCurr.IdcValSts
              REC_DcConnectorUSw_ValSts: accessed-variable=DcConnectorUSw.ValSts
              REC_DcDcCnvrPwrLossEstimd_PwrValSts: accessed-variable=DcDcCnvrPwrLossEstimd.PwrValSts
              REC_DcLinkIAct_ValSts: accessed-variable=DcLinkIAct.ValSts
              REC_DclnkUCtrlDeviation_Val: accessed-variable=DclnkUCtrlDeviation.Val
              REC_DcDcReac1TSw_ValSts: accessed-variable=DcDcReac1TSw.ValSts
              REC_DcDcReac2TSw_ValSts: accessed-variable=DcDcReac2TSw.ValSts
              REC_Em1AscRequest_Val: accessed-variable=Em1AscRequest.Val
              REC_Em2AscRequest_Val: accessed-variable=Em2AscRequest.Val
              REC_Pe1ThermDeratFac_MaxValSts: accessed-variable=Pe1ThermDeratFac.MaxValSts
              REC_Pe2ThermDeratFac_MaxValSts: accessed-variable=Pe2ThermDeratFac.MaxValSts
              REC_PeDcDcCnvrTDeratFac_FacValSts: accessed-variable=PeDcDcCnvrTDeratFac.FacValSts
              REC_IGBTMgrSy_NvmDrvSy_SopcResultCounters: accessed-variable=IGBTMgrSy_NvmDrvSy.SopcResultCounters
              REC_EmStopTriggered_Sts: accessed-variable=EmStopTriggered.Sts
              REC_VehVAct_ValSts: accessed-variable=VehVAct.ValSts
              REC_InsMonReadyForShutdown_FlgVal: accessed-variable=InsMonReadyForShutdown.FlgVal
              REC_InsMonUDcLinkFreezeReq_FlgVal: accessed-variable=InsMonUDcLinkFreezeReq.FlgVal
              REC_FaultLatchSig_Val: accessed-variable=FaultLatchSig.Val
              REC_Pe1FCapHotSpotTemp_ValSts: accessed-variable=Pe1FCapHotSpotTemp.ValSts
              REC_Pe2FCapHotSpotTemp_ValSts: accessed-variable=Pe2FCapHotSpotTemp.ValSts
              REC_InsMonPostRunCmplNvm_Val: accessed-variable=InsMonPostRunCmplNvm.Val
              REC_PECOutIf_stSpdlCtl_VW_PECOutIf_stSpdlCtl_VW: accessed-variable=PECOutIf_stSpdlCtl_VW.PECOutIf_stSpdlCtl_VW
              REC_HighVoltageSftyActvReactn_FlgVal: accessed-variable=HighVoltageSftyActvReactn.FlgVal
              REC_HsmLifeCycleState_Val: accessed-variable=HsmLifeCycleState.Val
              REC_WtrCooltInlTAct_TVal: accessed-variable=WtrCooltInlTAct.TVal
          data-send-points:
            67 x access:
              SEND_Em1AirgapTqSrc_SrcVal: accessed-variable=Em1AirgapTqSrc.SrcVal
              SEND_Em1AirgapTqTarAvl_TqVal: accessed-variable=Em1AirgapTqTarAvl.TqVal
              SEND_Em1IdqTar_IdQf: accessed-variable=Em1IdqTar.IdQf
              SEND_Em1IdqTar_IdVal: accessed-variable=Em1IdqTar.IdVal
              SEND_Em1IdqTar_IqQf: accessed-variable=Em1IdqTar.IqQf
              SEND_Em1IdqTar_IqVal: accessed-variable=Em1IdqTar.IqVal
              SEND_Em1MotPrm_FlxdQf: accessed-variable=Em1MotPrm.FlxdQf
              SEND_Em1MotPrm_FlxdVal: accessed-variable=Em1MotPrm.FlxdVal
              SEND_Em1MotPrm_FlxPrmntMagQf: accessed-variable=Em1MotPrm.FlxPrmntMagQf
              SEND_Em1MotPrm_FlxPrmntMagVal: accessed-variable=Em1MotPrm.FlxPrmntMagVal
              SEND_Em1MotPrm_FlxqQf: accessed-variable=Em1MotPrm.FlxqQf
              SEND_Em1MotPrm_FlxqVal: accessed-variable=Em1MotPrm.FlxqVal
              SEND_Em1MotPrm_LdQf: accessed-variable=Em1MotPrm.LdQf
              SEND_Em1MotPrm_LdVal: accessed-variable=Em1MotPrm.LdVal
              SEND_Em1MotPrm_LqQf: accessed-variable=Em1MotPrm.LqQf
              SEND_Em1MotPrm_LqVal: accessed-variable=Em1MotPrm.LqVal
              SEND_Em2AirgapTqSrc_SrcVal: accessed-variable=Em2AirgapTqSrc.SrcVal
              SEND_Em2AirgapTqTarAvl_TqVal: accessed-variable=Em2AirgapTqTarAvl.TqVal
              SEND_Em2IdqTar_IdQf: accessed-variable=Em2IdqTar.IdQf
              SEND_Em2IdqTar_IdVal: accessed-variable=Em2IdqTar.IdVal
              SEND_Em2IdqTar_IqQf: accessed-variable=Em2IdqTar.IqQf
              SEND_Em2IdqTar_IqVal: accessed-variable=Em2IdqTar.IqVal
              SEND_Em2MotPrm_FlxdQf: accessed-variable=Em2MotPrm.FlxdQf
              SEND_Em2MotPrm_FlxdVal: accessed-variable=Em2MotPrm.FlxdVal
              SEND_Em2MotPrm_FlxPrmntMagQf: accessed-variable=Em2MotPrm.FlxPrmntMagQf
              SEND_Em2MotPrm_FlxPrmntMagVal: accessed-variable=Em2MotPrm.FlxPrmntMagVal
              SEND_Em2MotPrm_FlxqQf: accessed-variable=Em2MotPrm.FlxqQf
              SEND_Em2MotPrm_FlxqVal: accessed-variable=Em2MotPrm.FlxqVal
              SEND_Em2MotPrm_LdQf: accessed-variable=Em2MotPrm.LdQf
              SEND_Em2MotPrm_LdVal: accessed-variable=Em2MotPrm.LdVal
              SEND_Em2MotPrm_LqQf: accessed-variable=Em2MotPrm.LqQf
              SEND_Em2MotPrm_LqVal: accessed-variable=Em2MotPrm.LqVal
              SEND_Pe1ModlnMethTar_Val: accessed-variable=Pe1ModlnMethTar.Val
              SEND_Pe1PwmFrqTar_FrqVal: accessed-variable=Pe1PwmFrqTar.FrqVal
              SEND_Pe2ModlnMethTar_Val: accessed-variable=Pe2ModlnMethTar.Val
              SEND_Pe2PwmFrqTar_FrqVal: accessed-variable=Pe2PwmFrqTar.FrqVal
              SEND_Em2TqCtrlModActvt_PECInIf_b_tqCtl_VW: accessed-variable=Em2TqCtrlModActvt.PECInIf_b_tqCtl_VW
              SEND_Em1MotPrm_RVal: accessed-variable=Em1MotPrm.RVal
              SEND_Em2MotPrm_RVal: accessed-variable=Em2MotPrm.RVal
              SEND_DcLnkUTar_UVal: accessed-variable=DcLnkUTar.UVal
              SEND_DcDcModeTar_StsVal: accessed-variable=DcDcModeTar.StsVal
              SEND_Eds1CtrlModActQm_ModVal: accessed-variable=Eds1CtrlModActQm.ModVal
              SEND_Eds2CtrlModActQm_ModVal: accessed-variable=Eds2CtrlModActQm.ModVal
              SEND_Asw1msEvents_Status: accessed-variable=Asw1msEvents.Status
              SEND_Em2SpdAbs_PECInIf_nAbs_VW: accessed-variable=Em2SpdAbs.PECInIf_nAbs_VW
              SEND_Em1AirgapTqEstimdQm_TqQf: accessed-variable=Em1AirgapTqEstimdQm.TqQf
              SEND_Em1AirgapTqEstimdQm_TqVal: accessed-variable=Em1AirgapTqEstimdQm.TqVal
              SEND_Em2AirgapTqEstimdQm_TqQf: accessed-variable=Em2AirgapTqEstimdQm.TqQf
              SEND_Em2AirgapTqEstimdQm_TqVal: accessed-variable=Em2AirgapTqEstimdQm.TqVal
              SEND_DcLnkVoltFild_DcLnkVSts: accessed-variable=DcLnkVoltFild.DcLnkVSts
              SEND_DclnkILim_IMaxValSts: accessed-variable=DclnkILim.IMaxValSts
              SEND_DclnkILim_IMinValSts: accessed-variable=DclnkILim.IMinValSts
              SEND_Em1SpdActvScLoInit_SpdValSts: accessed-variable=Em1SpdActvScLoInit.SpdValSts
              SEND_Em2SpdActvScLoInit_SpdValSts: accessed-variable=Em2SpdActvScLoInit.SpdValSts
              SEND_PECInIf_tqMax_VW_PECInIf_tqMax_VW: accessed-variable=PECInIf_tqMax_VW.PECInIf_tqMax_VW
              SEND_DcDcCnvrPwrMax_ValSts: accessed-variable=DcDcCnvrPwrMax.ValSts
              SEND_PECInIf_tqMin_VW_PECInIf_tqMin_VW: accessed-variable=PECInIf_tqMin_VW.PECInIf_tqMin_VW
              SEND_SopcPermission_Val: accessed-variable=SopcPermission.Val
              SEND_DcConnectorPwr_ValSts: accessed-variable=DcConnectorPwr.ValSts
              SEND_DcLnkUTar_ValSts: accessed-variable=DcLnkUTar.ValSts
              SEND_Em1MotPrm_LdDiffVal: accessed-variable=Em1MotPrm.LdDiffVal
              SEND_Em1MotPrm_LqDiffVal: accessed-variable=Em1MotPrm.LqDiffVal
              SEND_Em2MotPrm_LdDiffVal: accessed-variable=Em2MotPrm.LdDiffVal
              SEND_Em2MotPrm_LqDiffVal: accessed-variable=Em2MotPrm.LqDiffVal
              SEND_Em1ActvDchaSrcQm_FlgVal: accessed-variable=Em1ActvDchaSrcQm.FlgVal
              SEND_Em1PwmDcSrcQm_SrcVal: accessed-variable=Em1PwmDcSrcQm.SrcVal
              SEND_Em2PwmDcSrcQm_SrcVal: accessed-variable=Em2PwmDcSrcQm.SrcVal
        Exec250msAsw_Veh
          data-receive-point-by-arguments:
            29 x access:
              REC_IceCooltTAct_TVal: accessed-variable=IceCooltTAct.TVal
              REC_PeWtrCooltOutlTEstimd_TVal: accessed-variable=PeWtrCooltOutlTEstimd.TVal
              REC_PeWtrCooltOutlTEstimd_TValQf: accessed-variable=PeWtrCooltOutlTEstimd.TValQf
              REC_PeWtrCooltTTar_TVal: accessed-variable=PeWtrCooltTTar.TVal
              REC_PeWtrCooltVolFlowTar_VolFlowVal: accessed-variable=PeWtrCooltVolFlowTar.VolFlowVal
              REC_WtrCooltInlVolFlowAct_VolVal: accessed-variable=WtrCooltInlVolFlowAct.VolVal
              REC_Em2TqLimTracCtrl_TqMaxVal: accessed-variable=Em2TqLimTracCtrl.TqMaxVal
              REC_Em2TqLimTracCtrl_TqMinVal: accessed-variable=Em2TqLimTracCtrl.TqMinVal
              REC_AmbTAct_TVal: accessed-variable=AmbTAct.TVal
              REC_OilCooltVolFlowCalcd_VolFlowValSts: accessed-variable=OilCooltVolFlowCalcd.VolFlowValSts
              REC_VehTiOff_TiValSts: accessed-variable=VehTiOff.TiValSts
              REC_WtrCooltInlVolFlowAct_ValSts: accessed-variable=WtrCooltInlVolFlowAct.ValSts
              REC_Pe2IgbtTEstimd_ValSts: accessed-variable=Pe2IgbtTEstimd.ValSts
              REC_Pe1IgbtTEstimd_ValSts: accessed-variable=Pe1IgbtTEstimd.ValSts
              REC_PcbSensTemp_ValSts: accessed-variable=PcbSensTemp.ValSts
              REC_FCapSensTemp_ValSts: accessed-variable=FCapSensTemp.ValSts
              REC_FCapSensTemp_Val: accessed-variable=FCapSensTemp.Val
              REC_CbSensTemp_ValSts: accessed-variable=CbSensTemp.ValSts
              REC_PbSensTemp_ValSts: accessed-variable=PbSensTemp.ValSts
              REC_Clutch_Sts: accessed-variable=Clutch.Sts
              REC_DcDcReac1TSw_ValSts: accessed-variable=DcDcReac1TSw.ValSts
              REC_DcDcReac2TSw_ValSts: accessed-variable=DcDcReac2TSw.ValSts
              REC_IceCooltTAct_ValSts: accessed-variable=IceCooltTAct.ValSts
              REC_AmbTAct_ValSts: accessed-variable=AmbTAct.ValSts
              REC_PeWtrCooltInletTEstimd_ValSts: accessed-variable=PeWtrCooltInletTEstimd.ValSts
              REC_VehVAct_ValSts: accessed-variable=VehVAct.ValSts
              REC_EngCooltTQBit_ValSts: accessed-variable=EngCooltTQBit.ValSts
              REC_Pe1FCapHotSpotTemp_ValSts: accessed-variable=Pe1FCapHotSpotTemp.ValSts
              REC_Pe2FCapHotSpotTemp_ValSts: accessed-variable=Pe2FCapHotSpotTemp.ValSts
          data-send-points:
            24 x access:
              SEND_NDCPe1BswTemp_AcBusbarTEstimdPhaUVal: accessed-variable=NDCPe1BswTemp.AcBusbarTEstimdPhaUVal
              SEND_NDCPe1BswTemp_AcBusbarTEstimdPhaVVal: accessed-variable=NDCPe1BswTemp.AcBusbarTEstimdPhaVVal
              SEND_NDCPe1BswTemp_AcBusbarTEstimdPhaWVal: accessed-variable=NDCPe1BswTemp.AcBusbarTEstimdPhaWVal
              SEND_NDCPe2BswTemp_AcBusbarTEstimdPhaUVal: accessed-variable=NDCPe2BswTemp.AcBusbarTEstimdPhaUVal
              SEND_NDCPe2BswTemp_AcBusbarTEstimdPhaVVal: accessed-variable=NDCPe2BswTemp.AcBusbarTEstimdPhaVVal
              SEND_NDCPe2BswTemp_AcBusbarTEstimdPhaWVal: accessed-variable=NDCPe2BswTemp.AcBusbarTEstimdPhaWVal
              SEND_Asw250msEvents_Status: accessed-variable=Asw250msEvents.Status
              SEND_SmpOilTEstimd_TValSts: accessed-variable=SmpOilTEstimd.TValSts
              SEND_HeatExWtrCooltOutlT_TValSts: accessed-variable=HeatExWtrCooltOutlT.TValSts
              SEND_TOilCooltVolFlow_VolTarValSts: accessed-variable=TOilCooltVolFlow.VolTarValSts
              SEND_DhtWtrCooltVolFlow_VolTarValSts: accessed-variable=DhtWtrCooltVolFlow.VolTarValSts
              SEND_DhtWtrCooltT_TTarValSts: accessed-variable=DhtWtrCooltT.TTarValSts
              SEND_Em1RtmWarnTmpEm_Val: accessed-variable=Em1RtmWarnTempEm.Val
              SEND_Em1RtmWarnTmpPwr_Val: accessed-variable=Em1RtmWarnTempPwr.Val
              SEND_Em2RtmWarnTmpEm_Val: accessed-variable=Em2RtmWarnTempEm.Val
              SEND_Em2RtmWarnTmpPwr_Val: accessed-variable=Em2RtmWarnTempPwr.Val
              SEND_Em1StatorWindgTEstimd_TValSts: accessed-variable=Em1StatorWindgTEstimd.TValSts
              SEND_Em2StatorWindgTEstimd_TValSts: accessed-variable=Em2StatorWindgTEstimd.TValSts
              SEND_NDCPe2AcBusbarTEstimd_ValSts: accessed-variable=NDCPe2AcBusbarTEstimd.ValSts
              SEND_NDCPe1AcBusbarTEstimd_ValSts: accessed-variable=NDCPe1AcBusbarTEstimd.ValSts
              SEND_Em1RotorMagnTEstimd_TMaxVal: accessed-variable=Em1RotorMagnTEstimd.TMaxVal
              SEND_Em2RotorMagnTEstimd_TMaxVal: accessed-variable=Em2RotorMagnTEstimd.TMaxVal
              SEND_Em1StatorSurfaceTMax_ValSts: accessed-variable=Em1StatorSurfaceTMax.ValSts
              SEND_Em2StatorSurfaceTMax_ValSts: accessed-variable=Em2StatorSurfaceTMax.ValSts
        ExecExitAsw_Veh
          data-send-points:
            access SEND_ASW_EDS_TQ250_Nvmdrv_TValArray: accessed-variable=ASW_EDS_TQ250_Nvmdrv.TValArray
            access SEND_AswExit_Sts: accessed-variable=AswExit.Sts
          sync call SC_EolNvBlock_SetRamBlockStatus: operation=EolNvBlock.SetRamBlockStatus
          sync call SC_FastNvBlock_SetRamBlockStatus: operation=FastNvBlock.SetRamBlockStatus
          sync call SC_SafeNvBlock_SetRamBlockStatus: operation=SafeNvBlock.SetRamBlockStatus
        ExecInitAsw_Veh
          data-receive-point-by-arguments:
            access REC_Nvmdrv_ASW_EDS_TQ250_NvmSts: accessed-variable=Nvmdrv_ASW_EDS_TQ250.NvmSts
            access REC_Nvmdrv_ASW_EDS_TQ250_TValArray: accessed-variable=Nvmdrv_ASW_EDS_TQ250.TValArray
            access REC_NvmDrvInit_Sts: accessed-variable=NvmDrvInit.Sts
        Event_GetEventFailed
          data-send-points:
            access SEND_SopcPermission_Val: accessed-variable=SopcPermission.Val
          4 x sync call:
            SC_R_MonAProtSpdOutLimHiEm1_GetEventFailed: operation=R_MonAProtSpdOutLimHiEm1.GetEventFailed
            SC_R_MonAProtSpdOutLimHiEm2_GetEventFailed: operation=R_MonAProtSpdOutLimHiEm2.GetEventFailed
            SC_R_MonAProtTempOutLimHiEm1_GetEventFailed: operation=R_MonAProtTempOutLimHiEm1.GetEventFailed
            SC_R_MonAProtTempOutLimHiEm2_GetEventFailed: operation=R_MonAProtTempOutLimHiEm2.GetEventFailed
      swc service dependency EolNvBlock: assigned-datas=role-based-data-assignment={role=ramBlock, used-data-element=EolNvBlock_RamMirror}, assigned-ports=role-based-port-assignment={port-prototype=EolNvBlock, role=NvMService}
        service-needs:
          nv block needs EolNvBlock: calc-ram-block-crc=true, n-data-sets=0, ram-block-status-control=API, reliability=ERROR-CORRECTION, restore-at-start=true, store-at-shutdown=true, use-auto-validation-at-shut-down=true, use-crc-comp-mechanism=true
      swc service dependency FastlNvBlock: assigned-datas=role-based-data-assignment={role=ramBlock, used-data-element=FastNvBlock_RamMirror}, assigned-ports=role-based-port-assignment={port-prototype=FastNvBlock, role=NvMService}
        service-needs:
          nv block needs FastlNvBlock: calc-ram-block-crc=true, n-data-sets=0, ram-block-status-control=API, reliability=ERROR-CORRECTION, restore-at-start=true, store-at-shutdown=true, use-auto-validation-at-shut-down=true, use-crc-comp-mechanism=true
      swc service dependency SafeNvBlock: assigned-datas=role-based-data-assignment={role=ramBlock, used-data-element=SafeNvBlock_RamMirror}, assigned-ports=role-based-port-assignment={port-prototype=SafeNvBlock, role=NvMService}
        service-needs:
          nv block needs SafeNvBlock: calc-ram-block-crc=true, n-data-sets=0, ram-block-status-control=API, reliability=ERROR-CORRECTION, restore-at-start=true, store-at-shutdown=true, use-auto-validation-at-shut-down=true, use-crc-comp-mechanism=true
  swc implementation ASW_EDS_TQ250_Implementation: programming-language=C, sw-version=1.0.0, vendor-id=1, behavior=ASW_EDS_TQ250_InternalBehavior
    code-descriptors:
      code Default: artifact-descriptors=autosar-engineering-object={short-label=DEFAULT, category=SWSRC}
